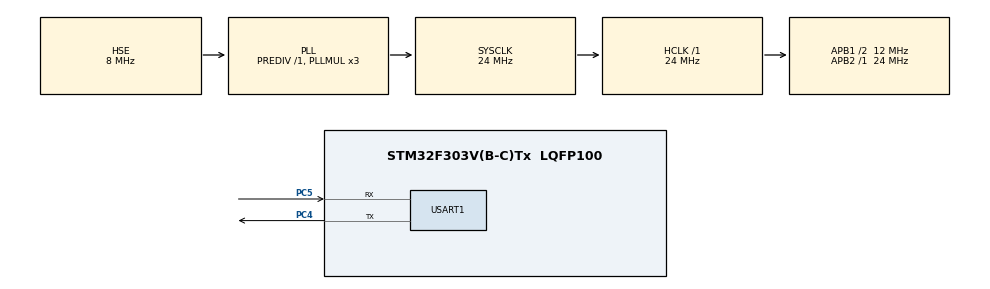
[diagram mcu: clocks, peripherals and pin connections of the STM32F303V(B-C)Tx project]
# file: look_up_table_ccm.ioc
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Mcu.Family=STM32F3
Mcu.Name=STM32F303V(B-C)Tx
Mcu.Package=LQFP100
NVIC.PriorityGroup=NVIC_PRIORITYGROUP_4
NVIC.TIM2_IRQn=true\:0\:0\:false\:false\:true\:true\:true
PC4.Mode=Asynchronous
PC4.Signal=USART1_TX
PC5.Mode=Asynchronous
PC5.Signal=USART1_RX
PF0-OSC_IN.Mode=HSE-External-Oscillator
PF0-OSC_IN.Signal=RCC_OSC_IN
PF1-OSC_OUT.Mode=HSE-External-Oscillator
PF1-OSC_OUT.Signal=RCC_OSC_OUT
ProjectManager.HeapSize=0x200
ProjectManager.StackSize=0x400
ProjectManager.TargetToolchain=STM32CubeIDE
RCC.AHBFreq_Value=24000000
RCC.APB1CLKDivider=RCC_HCLK_DIV2
RCC.APB1Freq_Value=12000000
RCC.APB1TimFreq_Value=24000000
RCC.APB2Freq_Value=24000000
RCC.APB2TimFreq_Value=24000000
RCC.CortexFreq_Value=24000000
RCC.HCLKFreq_Value=24000000
RCC.HSE_VALUE=8000000
RCC.HSI_VALUE=8000000
RCC.LSE_VALUE=32768
RCC.PLLMUL=RCC_PLL_MUL3
RCC.PLLSourceVirtual=RCC_PLLSOURCE_HSE
RCC.SYSCLKFreq_VALUE=24000000
RCC.SYSCLKSourceVirtual=RCC_SYSCLKSOURCE_PLLCLK
RCC.USBFreq_Value=24000000
TIM2.AutoReloadPreload=TIM_AUTORELOAD_PRELOAD_DISABLE
TIM2.Period=(1000000-1)
TIM2.Prescaler=(24-1)
USART1.VirtualMode-Asynchronous=VM_ASYNC
VP_TIM2_VS_ClockSourceINT.Mode=Internal
board=custom

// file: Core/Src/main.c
/* USER CODE BEGIN Header */
/**
  ******************************************************************************
  * @file           : main.c
  * @brief          : Main program body
  ******************************************************************************
  * @attention
  *
  * <h2><center>&copy; Copyright (c) 2021 STMicroelectronics.
  * All rights reserved.</center></h2>
  *
  * This software component is licensed by ST under BSD 3-Clause license,
  * the "License"; You may not use this file except in compliance with the
  * License. You may obtain a copy of the License at:
  *                        opensource.org/licenses/BSD-3-Clause
  *
  ******************************************************************************
  */
/* USER CODE END Header */
#include "main.h"

/* USER CODE BEGIN PM */
TIM_HandleTypeDef htim2;

UART_HandleTypeDef huart1;

/*data size*/
#define INPUT_ARRAY_SIZE_1750

/*functions data*/
#define FUNCTIONS_DATA_IN_FLASH
//#define FUNCTIONS_DATA_IN_CCM

/*program allocation*/
#define PROGRAM_IN_CCM

/*input data allocation*/
#define INPUT_DATA_IN_CCM

float output=0;

/* USER CODE END PM */

TIM_HandleTypeDef htim2;

UART_HandleTypeDef huart1;

/* USER CODE BEGIN PV */
#ifdef PROGRAM_IN_CCM
   __attribute__((section(".ccmram")))
#endif
   void computeArraySin(float * arr_input, float * arr_keys , float * arr_values, int n_lut, int n_input){
       for(int i=0; i<n_input; i++){
           for (int k=0; k<n_lut; k++){
   	        if (*(arr_keys+k+1) >= *(arr_input+i)){
               output = *(arr_values+k) + (*(arr_values+k+1)-*(arr_values+k))*(*(arr_input+i) - *(arr_keys + k))/(*(arr_keys+k+1)-*(arr_keys+k));
               break;
               };
           };
       }
   }

#ifdef FUNCTIONS_DATA_IN_FLASH
   const
#endif
#ifdef FUNCTIONS_DATA_IN_CCM
   __attribute__((section(".ccmramdata")))
#endif
   float arr_keys[721] = {
   0.0, 0.5, 1.0, 1.5, 2.0, 2.5, 3.0, 3.5, 4.0, 4.5, 5.0, 5.5, 6.0, 6.5, 7.0, 7.5, 8.0, 8.5, 9.0, 9.5, 10.0, 10.5, 11.0, 11.5, 12.0, 12.5, 13.0, 13.5, 14.0, 14.5, 15.0, 15.5, 16.0, 16.5, 17.0, 17.5, 18.0, 18.5, 19.0, 19.5, 20.0, 20.5, 21.0, 21.5, 22.0, 22.5, 23.0, 23.5, 24.0, 24.5,
   25.0, 25.5, 26.0, 26.5, 27.0, 27.5, 28.0, 28.5, 29.0, 29.5, 30.0, 30.5, 31.0, 31.5, 32.0, 32.5, 33.0, 33.5, 34.0, 34.5, 35.0, 35.5, 36.0, 36.5, 37.0, 37.5, 38.0, 38.5, 39.0, 39.5, 40.0, 40.5, 41.0, 41.5, 42.0, 42.5, 43.0, 43.5, 44.0, 44.5, 45.0, 45.5, 46.0, 46.5, 47.0, 47.5, 48.0, 48.5, 49.0, 49.5,
   50.0, 50.5, 51.0, 51.5, 52.0, 52.5, 53.0, 53.5, 54.0, 54.5, 55.0, 55.5, 56.0, 56.5, 57.0, 57.5, 58.0, 58.5, 59.0, 59.5, 60.0, 60.5, 61.0, 61.5, 62.0, 62.5, 63.0, 63.5, 64.0, 64.5, 65.0, 65.5, 66.0, 66.5, 67.0, 67.5, 68.0, 68.5, 69.0, 69.5, 70.0, 70.5, 71.0, 71.5, 72.0, 72.5, 73.0, 73.5, 74.0, 74.5,
   75.0, 75.5, 76.0, 76.5, 77.0, 77.5, 78.0, 78.5, 79.0, 79.5, 80.0, 80.5, 81.0, 81.5, 82.0, 82.5, 83.0, 83.5, 84.0, 84.5, 85.0, 85.5, 86.0, 86.5, 87.0, 87.5, 88.0, 88.5, 89.0, 89.5, 90.0, 90.5, 91.0, 91.5, 92.0, 92.5, 93.0, 93.5, 94.0, 94.5, 95.0, 95.5, 96.0, 96.5, 97.0, 97.5, 98.0, 98.5, 99.0, 99.5,
   100.0, 100.5, 101.0, 101.5, 102.0, 102.5, 103.0, 103.5, 104.0, 104.5, 105.0, 105.5, 106.0, 106.5, 107.0, 107.5, 108.0, 108.5, 109.0, 109.5, 110.0, 110.5, 111.0, 111.5, 112.0, 112.5, 113.0, 113.5, 114.0, 114.5, 115.0, 115.5, 116.0, 116.5, 117.0, 117.5, 118.0, 118.5, 119.0, 119.5, 120.0, 120.5, 121.0, 121.5, 122.0, 122.5, 123.0, 123.5, 124.0, 124.5,
   125.0, 125.5, 126.0, 126.5, 127.0, 127.5, 128.0, 128.5, 129.0, 129.5, 130.0, 130.5, 131.0, 131.5, 132.0, 132.5, 133.0, 133.5, 134.0, 134.5, 135.0, 135.5, 136.0, 136.5, 137.0, 137.5, 138.0, 138.5, 139.0, 139.5, 140.0, 140.5, 141.0, 141.5, 142.0, 142.5, 143.0, 143.5, 144.0, 144.5, 145.0, 145.5, 146.0, 146.5, 147.0, 147.5, 148.0, 148.5, 149.0, 149.5,
   150.0, 150.5, 151.0, 151.5, 152.0, 152.5, 153.0, 153.5, 154.0, 154.5, 155.0, 155.5, 156.0, 156.5, 157.0, 157.5, 158.0, 158.5, 159.0, 159.5, 160.0, 160.5, 161.0, 161.5, 162.0, 162.5, 163.0, 163.5, 164.0, 164.5, 165.0, 165.5, 166.0, 166.5, 167.0, 167.5, 168.0, 168.5, 169.0, 169.5, 170.0, 170.5, 171.0, 171.5, 172.0, 172.5, 173.0, 173.5, 174.0, 174.5,
   175.0, 175.5, 176.0, 176.5, 177.0, 177.5, 178.0, 178.5, 179.0, 179.5, 180.0, 180.5, 181.0, 181.5, 182.0, 182.5, 183.0, 183.5, 184.0, 184.5, 185.0, 185.5, 186.0, 186.5, 187.0, 187.5, 188.0, 188.5, 189.0, 189.5, 190.0, 190.5, 191.0, 191.5, 192.0, 192.5, 193.0, 193.5, 194.0, 194.5, 195.0, 195.5, 196.0, 196.5, 197.0, 197.5, 198.0, 198.5, 199.0, 199.5,
   200.0, 200.5, 201.0, 201.5, 202.0, 202.5, 203.0, 203.5, 204.0, 204.5, 205.0, 205.5, 206.0, 206.5, 207.0, 207.5, 208.0, 208.5, 209.0, 209.5, 210.0, 210.5, 211.0, 211.5, 212.0, 212.5, 213.0, 213.5, 214.0, 214.5, 215.0, 215.5, 216.0, 216.5, 217.0, 217.5, 218.0, 218.5, 219.0, 219.5, 220.0, 220.5, 221.0, 221.5, 222.0, 222.5, 223.0, 223.5, 224.0, 224.5,
   225.0, 225.5, 226.0, 226.5, 227.0, 227.5, 228.0, 228.5, 229.0, 229.5, 230.0, 230.5, 231.0, 231.5, 232.0, 232.5, 233.0, 233.5, 234.0, 234.5, 235.0, 235.5, 236.0, 236.5, 237.0, 237.5, 238.0, 238.5, 239.0, 239.5, 240.0, 240.5, 241.0, 241.5, 242.0, 242.5, 243.0, 243.5, 244.0, 244.5, 245.0, 245.5, 246.0, 246.5, 247.0, 247.5, 248.0, 248.5, 249.0, 249.5,
   250.0, 250.5, 251.0, 251.5, 252.0, 252.5, 253.0, 253.5, 254.0, 254.5, 255.0, 255.5, 256.0, 256.5, 257.0, 257.5, 258.0, 258.5, 259.0, 259.5, 260.0, 260.5, 261.0, 261.5, 262.0, 262.5, 263.0, 263.5, 264.0, 264.5, 265.0, 265.5, 266.0, 266.5, 267.0, 267.5, 268.0, 268.5, 269.0, 269.5, 270.0, 270.5, 271.0, 271.5, 272.0, 272.5, 273.0, 273.5, 274.0, 274.5,
   275.0, 275.5, 276.0, 276.5, 277.0, 277.5, 278.0, 278.5, 279.0, 279.5, 280.0, 280.5, 281.0, 281.5, 282.0, 282.5, 283.0, 283.5, 284.0, 284.5, 285.0, 285.5, 286.0, 286.5, 287.0, 287.5, 288.0, 288.5, 289.0, 289.5, 290.0, 290.5, 291.0, 291.5, 292.0, 292.5, 293.0, 293.5, 294.0, 294.5, 295.0, 295.5, 296.0, 296.5, 297.0, 297.5, 298.0, 298.5, 299.0, 299.5,
   300.0, 300.5, 301.0, 301.5, 302.0, 302.5, 303.0, 303.5, 304.0, 304.5, 305.0, 305.5, 306.0, 306.5, 307.0, 307.5, 308.0, 308.5, 309.0, 309.5, 310.0, 310.5, 311.0, 311.5, 312.0, 312.5, 313.0, 313.5, 314.0, 314.5, 315.0, 315.5, 316.0, 316.5, 317.0, 317.5, 318.0, 318.5, 319.0, 319.5, 320.0, 320.5, 321.0, 321.5, 322.0, 322.5, 323.0, 323.5, 324.0, 324.5,
   325.0, 325.5, 326.0, 326.5, 327.0, 327.5, 328.0, 328.5, 329.0, 329.5, 330.0, 330.5, 331.0, 331.5, 332.0, 332.5, 333.0, 333.5, 334.0, 334.5, 335.0, 335.5, 336.0, 336.5, 337.0, 337.5, 338.0, 338.5, 339.0, 339.5, 340.0, 340.5, 341.0, 341.5, 342.0, 342.5, 343.0, 343.5, 344.0, 344.5, 345.0, 345.5, 346.0, 346.5, 347.0, 347.5, 348.0, 348.5, 349.0, 349.5,
   350.0, 350.5, 351.0, 351.5, 352.0, 352.5, 353.0, 353.5, 354.0, 354.5, 355.0, 355.5, 356.0, 356.5, 357.0, 357.5, 358.0, 358.5, 359.0, 359.5, 360.0};

#ifdef FUNCTIONS_DATA_IN_FLASH
   const
#endif
#ifdef FUNCTIONS_DATA_IN_CCM
   __attribute__((section(".ccmramdata")))
#endif
   float arr_values[721] ={
   0.0, 0.0087, 0.0175, 0.0262, 0.0349, 0.0436, 0.0523, 0.061, 0.0698, 0.0785, 0.0872, 0.0958, 0.1045, 0.1132, 0.1219, 0.1305, 0.1392, 0.1478, 0.1564, 0.165, 0.1736, 0.1822, 0.1908, 0.1994, 0.2079, 0.2164, 0.225, 0.2334, 0.2419, 0.2504, 0.2588, 0.2672, 0.2756, 0.284, 0.2924, 0.3007, 0.309, 0.3173, 0.3256, 0.3338, 0.342, 0.3502, 0.3584, 0.3665, 0.3746, 0.3827, 0.3907, 0.3987, 0.4067, 0.4147,
   0.4226, 0.4305, 0.4384, 0.4462, 0.454, 0.4617, 0.4695, 0.4772, 0.4848, 0.4924, 0.5, 0.5075, 0.515, 0.5225, 0.5299, 0.5373, 0.5446, 0.5519, 0.5592, 0.5664, 0.5736, 0.5807, 0.5878, 0.5948, 0.6018, 0.6088, 0.6157, 0.6225, 0.6293, 0.6361, 0.6428, 0.6494, 0.6561, 0.6626, 0.6691, 0.6756, 0.682, 0.6884, 0.6947, 0.7009, 0.7071, 0.7133, 0.7193, 0.7254, 0.7314, 0.7373, 0.7431, 0.749, 0.7547, 0.7604,
   0.766, 0.7716, 0.7771, 0.7826, 0.788, 0.7934, 0.7986, 0.8039, 0.809, 0.8141, 0.8192, 0.8241, 0.829, 0.8339, 0.8387, 0.8434, 0.848, 0.8526, 0.8572, 0.8616, 0.866, 0.8704, 0.8746, 0.8788, 0.8829, 0.887, 0.891, 0.8949, 0.8988, 0.9026, 0.9063, 0.91, 0.9135, 0.9171, 0.9205, 0.9239, 0.9272, 0.9304, 0.9336, 0.9367, 0.9397, 0.9426, 0.9455, 0.9483, 0.9511, 0.9537, 0.9563, 0.9588, 0.9613, 0.9636,
   0.9659, 0.9681, 0.9703, 0.9724, 0.9744, 0.9763, 0.9781, 0.9799, 0.9816, 0.9833, 0.9848, 0.9863, 0.9877, 0.989, 0.9903, 0.9914, 0.9925, 0.9936, 0.9945, 0.9954, 0.9962, 0.9969, 0.9976, 0.9981, 0.9986, 0.999, 0.9994, 0.9997, 0.9998, 1.0, 1.0, 1.0, 0.9998, 0.9997, 0.9994, 0.999, 0.9986, 0.9981, 0.9976, 0.9969, 0.9962, 0.9954, 0.9945, 0.9936, 0.9925, 0.9914, 0.9903, 0.989, 0.9877, 0.9863,
   0.9848, 0.9833, 0.9816, 0.9799, 0.9781, 0.9763, 0.9744, 0.9724, 0.9703, 0.9681, 0.9659, 0.9636, 0.9613, 0.9588, 0.9563, 0.9537, 0.9511, 0.9483, 0.9455, 0.9426, 0.9397, 0.9367, 0.9336, 0.9304, 0.9272, 0.9239, 0.9205, 0.9171, 0.9135, 0.91, 0.9063, 0.9026, 0.8988, 0.8949, 0.891, 0.887, 0.8829, 0.8788, 0.8746, 0.8704, 0.866, 0.8616, 0.8572, 0.8526, 0.848, 0.8434, 0.8387, 0.8339, 0.829, 0.8241,
   0.8192, 0.8141, 0.809, 0.8039, 0.7986, 0.7934, 0.788, 0.7826, 0.7771, 0.7716, 0.766, 0.7604, 0.7547, 0.749, 0.7431, 0.7373, 0.7314, 0.7254, 0.7193, 0.7133, 0.7071, 0.7009, 0.6947, 0.6884, 0.682, 0.6756, 0.6691, 0.6626, 0.6561, 0.6494, 0.6428, 0.6361, 0.6293, 0.6225, 0.6157, 0.6088, 0.6018, 0.5948, 0.5878, 0.5807, 0.5736, 0.5664, 0.5592, 0.5519, 0.5446, 0.5373, 0.5299, 0.5225, 0.515, 0.5075,
   0.5, 0.4924, 0.4848, 0.4772, 0.4695, 0.4617, 0.454, 0.4462, 0.4384, 0.4305, 0.4226, 0.4147, 0.4067, 0.3987, 0.3907, 0.3827, 0.3746, 0.3665, 0.3584, 0.3502, 0.342, 0.3338, 0.3256, 0.3173, 0.309, 0.3007, 0.2924, 0.284, 0.2756, 0.2672, 0.2588, 0.2504, 0.2419, 0.2334, 0.225, 0.2164, 0.2079, 0.1994, 0.1908, 0.1822, 0.1736, 0.165, 0.1564, 0.1478, 0.1392, 0.1305, 0.1219, 0.1132, 0.1045, 0.0958,
   0.0872, 0.0785, 0.0698, 0.061, 0.0523, 0.0436, 0.0349, 0.0262, 0.0175, 0.0087, 0.0, -0.0087, -0.0175, -0.0262, -0.0349, -0.0436, -0.0523, -0.061, -0.0698, -0.0785, -0.0872, -0.0958, -0.1045, -0.1132, -0.1219, -0.1305, -0.1392, -0.1478, -0.1564, -0.165, -0.1736, -0.1822, -0.1908, -0.1994, -0.2079, -0.2164, -0.225, -0.2334, -0.2419, -0.2504, -0.2588, -0.2672, -0.2756, -0.284, -0.2924, -0.3007, -0.309, -0.3173, -0.3256, -0.3338,
   -0.342, -0.3502, -0.3584, -0.3665, -0.3746, -0.3827, -0.3907, -0.3987, -0.4067, -0.4147, -0.4226, -0.4305, -0.4384, -0.4462, -0.454, -0.4617, -0.4695, -0.4772, -0.4848, -0.4924, -0.5, -0.5075, -0.515, -0.5225, -0.5299, -0.5373, -0.5446, -0.5519, -0.5592, -0.5664, -0.5736, -0.5807, -0.5878, -0.5948, -0.6018, -0.6088, -0.6157, -0.6225, -0.6293, -0.6361, -0.6428, -0.6494, -0.6561, -0.6626, -0.6691, -0.6756, -0.682, -0.6884, -0.6947, -0.7009,
   -0.7071, -0.7133, -0.7193, -0.7254, -0.7314, -0.7373, -0.7431, -0.749, -0.7547, -0.7604, -0.766, -0.7716, -0.7771, -0.7826, -0.788, -0.7934, -0.7986, -0.8039, -0.809, -0.8141, -0.8192, -0.8241, -0.829, -0.8339, -0.8387, -0.8434, -0.848, -0.8526, -0.8572, -0.8616, -0.866, -0.8704, -0.8746, -0.8788, -0.8829, -0.887, -0.891, -0.8949, -0.8988, -0.9026, -0.9063, -0.91, -0.9135, -0.9171, -0.9205, -0.9239, -0.9272, -0.9304, -0.9336, -0.9367,
   -0.9397, -0.9426, -0.9455, -0.9483, -0.9511, -0.9537, -0.9563, -0.9588, -0.9613, -0.9636, -0.9659, -0.9681, -0.9703, -0.9724, -0.9744, -0.9763, -0.9781, -0.9799, -0.9816, -0.9833, -0.9848, -0.9863, -0.9877, -0.989, -0.9903, -0.9914, -0.9925, -0.9936, -0.9945, -0.9954, -0.9962, -0.9969, -0.9976, -0.9981, -0.9986, -0.999, -0.9994, -0.9997, -0.9998, -1.0, -1.0, -1.0, -0.9998, -0.9997, -0.9994, -0.999, -0.9986, -0.9981, -0.9976, -0.9969,
   -0.9962, -0.9954, -0.9945, -0.9936, -0.9925, -0.9914, -0.9903, -0.989, -0.9877, -0.9863, -0.9848, -0.9833, -0.9816, -0.9799, -0.9781, -0.9763, -0.9744, -0.9724, -0.9703, -0.9681, -0.9659, -0.9636, -0.9613, -0.9588, -0.9563, -0.9537, -0.9511, -0.9483, -0.9455, -0.9426, -0.9397, -0.9367, -0.9336, -0.9304, -0.9272, -0.9239, -0.9205, -0.9171, -0.9135, -0.91, -0.9063, -0.9026, -0.8988, -0.8949, -0.891, -0.887, -0.8829, -0.8788, -0.8746, -0.8704,
   -0.866, -0.8616, -0.8572, -0.8526, -0.848, -0.8434, -0.8387, -0.8339, -0.829, -0.8241, -0.8192, -0.8141, -0.809, -0.8039, -0.7986, -0.7934, -0.788, -0.7826, -0.7771, -0.7716, -0.766, -0.7604, -0.7547, -0.749, -0.7431, -0.7373, -0.7314, -0.7254, -0.7193, -0.7133, -0.7071, -0.7009, -0.6947, -0.6884, -0.682, -0.6756, -0.6691, -0.6626, -0.6561, -0.6494, -0.6428, -0.6361, -0.6293, -0.6225, -0.6157, -0.6088, -0.6018, -0.5948, -0.5878, -0.5807,
   -0.5736, -0.5664, -0.5592, -0.5519, -0.5446, -0.5373, -0.5299, -0.5225, -0.515, -0.5075, -0.5, -0.4924, -0.4848, -0.4772, -0.4695, -0.4617, -0.454, -0.4462, -0.4384, -0.4305, -0.4226, -0.4147, -0.4067, -0.3987, -0.3907, -0.3827, -0.3746, -0.3665, -0.3584, -0.3502, -0.342, -0.3338, -0.3256, -0.3173, -0.309, -0.3007, -0.2924, -0.284, -0.2756, -0.2672, -0.2588, -0.2504, -0.2419, -0.2334, -0.225, -0.2164, -0.2079, -0.1994, -0.1908, -0.1822,
   -0.1736, -0.165, -0.1564, -0.1478, -0.1392, -0.1305, -0.1219, -0.1132, -0.1045, -0.0958, -0.0872, -0.0785, -0.0698, -0.061, -0.0523, -0.0436, -0.0349, -0.0262, -0.0175, -0.0087, -0.0};

#ifdef INPUT_ARRAY_SIZE_100
#ifdef INPUT_DATA_IN_CCM
   __attribute__((section(".ccmramdata")))
#endif

   float arr_input[100] ={ 48.3711 ,305.0761 ,274.9589 ,91.8248 ,178.3566 ,161.8168 ,234.5735 ,283.9404 ,33.7895 ,10.2051 ,300.8754 ,155.7961 ,274.4208 ,0.7582 ,160.3394 ,259.7544 ,82.3544 ,340.2975 ,324.5139 ,11.0124 ,9.1605 ,194.9085 ,338.0937 ,137.2335 ,77.9758 ,151.9620 ,10.4547 ,79.8090 ,157.6395 ,178.4924 ,83.9104 ,83.1120 ,78.7612 ,165.4572 ,104.3214 ,7.7363 ,301.5281 ,200.3236 ,231.2260 ,66.9263 ,357.3156 ,309.5808 ,43.5204 ,119.7703 ,259.7344 ,256.0290 ,337.1186 ,151.9585 ,298.8128 ,241.3100 ,
      		109.2127 ,211.5290 ,317.6924 ,304.6311 ,181.9022 ,212.0408 ,12.4293 ,87.3864 ,287.0655 ,149.1530 ,62.2827 ,197.5676 ,253.0947 ,242.8149 ,134.8931 ,158.0262 ,183.0335 ,280.2393 ,187.5378 ,141.5718 ,176.2897 ,10.6470 ,15.6554 ,253.2176 ,353.9476 ,213.5461 ,141.6959 ,61.3257 ,180.8059 ,353.5476 ,277.3883 ,194.2623 ,309.7043 ,83.5834 ,184.9578 ,342.8883 ,208.0061 ,165.2874 ,96.9406 ,197.2787 ,344.5619 ,2.0553 ,282.1159 ,295.3749 ,319.0246 ,266.5812 ,291.2904 ,186.7242 ,202.0888 ,153.3926};
#endif

#ifdef INPUT_ARRAY_SIZE_200
#ifdef INPUT_DATA_IN_CCM
   __attribute__((section(".ccmramdata")))
#endif
   float arr_input[200] = {48.3711 ,305.0761 ,274.9589 ,91.8248 ,178.3566 ,161.8168 ,234.5735 ,283.9404 ,33.7895 ,10.2051 ,300.8754 ,155.7961 ,274.4208 ,0.7582 ,160.3394 ,259.7544 ,82.3544 ,340.2975 ,324.5139 ,11.0124 ,9.1605 ,194.9085 ,338.0937 ,137.2335 ,77.9758 ,151.9620 ,10.4547 ,79.8090 ,157.6395 ,178.4924 ,83.9104 ,83.1120 ,78.7612 ,165.4572 ,104.3214 ,7.7363 ,301.5281 ,200.3236 ,231.2260 ,66.9263 ,357.3156 ,309.5808 ,43.5204 ,119.7703 ,259.7344 ,256.0290 ,337.1186 ,151.9585 ,298.8128 ,241.3100 ,
    		109.2127 ,211.5290 ,317.6924 ,304.6311 ,181.9022 ,212.0408 ,12.4293 ,87.3864 ,287.0655 ,149.1530 ,62.2827 ,197.5676 ,253.0947 ,242.8149 ,134.8931 ,158.0262 ,183.0335 ,280.2393 ,187.5378 ,141.5718 ,176.2897 ,10.6470 ,15.6554 ,253.2176 ,353.9476 ,213.5461 ,141.6959 ,61.3257 ,180.8059 ,353.5476 ,277.3883 ,194.2623 ,309.7043 ,83.5834 ,184.9578 ,342.8883 ,208.0061 ,165.2874 ,96.9406 ,197.2787 ,344.5619 ,2.0553 ,282.1159 ,295.3749 ,319.0246 ,266.5812 ,291.2904 ,186.7242 ,202.0888 ,153.3926 ,
    		20.2044 ,313.2037 ,205.1998 ,71.9422 ,181.6994 ,174.5730 ,128.4444 ,124.5881 ,193.8524 ,224.4562 ,220.4829 ,164.9328 ,10.0710 ,82.6578 ,63.7961 ,210.4059 ,309.9632 ,287.4380 ,286.9551 ,293.9175 ,91.9059 ,303.0281 ,242.3209 ,29.9643 ,6.0086 ,5.2416 ,272.0112 ,89.8413 ,39.4159 ,224.9288 ,123.9922 ,25.0255 ,57.4652 ,189.8569 ,60.5322 ,98.2492 ,256.1724 ,163.6926 ,115.9206 ,170.5576 ,8.5084 ,139.1606 ,151.5307 ,67.6941 ,39.1542 ,323.9347 ,183.6418 ,75.2728 ,218.0335 ,294.1343 ,
    		7.4945 ,6.4312 ,52.7262 ,258.7808 ,57.6819 ,253.6580 ,244.1433 ,196.0928 ,79.4159 ,351.2140 ,287.2119 ,185.9758 ,80.3505 ,233.4623 ,142.1633 ,207.3045 ,115.6485 ,227.1412 ,21.1626 ,107.4981 ,348.4452 ,315.1923 ,110.2992 ,309.0652 ,111.7309 ,338.1438 ,267.7832 ,149.8220 ,90.8489 ,3.0529 ,316.3384 ,13.6500 ,294.9891 ,346.3924 ,205.3010 ,61.7462 ,312.4012 ,350.5591 ,253.4483 ,183.1945 ,136.0688 ,124.8951 ,74.0742 ,242.6951 ,155.8620 ,69.8827 ,37.5927 ,239.7447 ,106.5862 ,179.9280};
#endif

#ifdef INPUT_ARRAY_SIZE_300
#ifdef INPUT_DATA_IN_CCM
   __attribute__((section(".ccmramdata")))
#endif
   float arr_input[300] = {48.3711 ,305.0761 ,274.9589 ,91.8248 ,178.3566 ,161.8168 ,234.5735 ,283.9404 ,33.7895 ,10.2051 ,300.8754 ,155.7961 ,274.4208 ,0.7582 ,160.3394 ,259.7544 ,82.3544 ,340.2975 ,324.5139 ,11.0124 ,9.1605 ,194.9085 ,338.0937 ,137.2335 ,77.9758 ,151.9620 ,10.4547 ,79.8090 ,157.6395 ,178.4924 ,83.9104 ,83.1120 ,78.7612 ,165.4572 ,104.3214 ,7.7363 ,301.5281 ,200.3236 ,231.2260 ,66.9263 ,357.3156 ,309.5808 ,43.5204 ,119.7703 ,259.7344 ,256.0290 ,337.1186 ,151.9585 ,298.8128 ,241.3100 ,
      		109.2127 ,211.5290 ,317.6924 ,304.6311 ,181.9022 ,212.0408 ,12.4293 ,87.3864 ,287.0655 ,149.1530 ,62.2827 ,197.5676 ,253.0947 ,242.8149 ,134.8931 ,158.0262 ,183.0335 ,280.2393 ,187.5378 ,141.5718 ,176.2897 ,10.6470 ,15.6554 ,253.2176 ,353.9476 ,213.5461 ,141.6959 ,61.3257 ,180.8059 ,353.5476 ,277.3883 ,194.2623 ,309.7043 ,83.5834 ,184.9578 ,342.8883 ,208.0061 ,165.2874 ,96.9406 ,197.2787 ,344.5619 ,2.0553 ,282.1159 ,295.3749 ,319.0246 ,266.5812 ,291.2904 ,186.7242 ,202.0888 ,153.3926 ,
      		20.2044 ,313.2037 ,205.1998 ,71.9422 ,181.6994 ,174.5730 ,128.4444 ,124.5881 ,193.8524 ,224.4562 ,220.4829 ,164.9328 ,10.0710 ,82.6578 ,63.7961 ,210.4059 ,309.9632 ,287.4380 ,286.9551 ,293.9175 ,91.9059 ,303.0281 ,242.3209 ,29.9643 ,6.0086 ,5.2416 ,272.0112 ,89.8413 ,39.4159 ,224.9288 ,123.9922 ,25.0255 ,57.4652 ,189.8569 ,60.5322 ,98.2492 ,256.1724 ,163.6926 ,115.9206 ,170.5576 ,8.5084 ,139.1606 ,151.5307 ,67.6941 ,39.1542 ,323.9347 ,183.6418 ,75.2728 ,218.0335 ,294.1343 ,
      		7.4945 ,6.4312 ,52.7262 ,258.7808 ,57.6819 ,253.6580 ,244.1433 ,196.0928 ,79.4159 ,351.2140 ,287.2119 ,185.9758 ,80.3505 ,233.4623 ,142.1633 ,207.3045 ,115.6485 ,227.1412 ,21.1626 ,107.4981 ,348.4452 ,315.1923 ,110.2992 ,309.0652 ,111.7309 ,338.1438 ,267.7832 ,149.8220 ,90.8489 ,3.0529 ,316.3384 ,13.6500 ,294.9891 ,346.3924 ,205.3010 ,61.7462 ,312.4012 ,350.5591 ,253.4483 ,183.1945 ,136.0688 ,124.8951 ,74.0742 ,242.6951 ,155.8620 ,69.8827 ,37.5927 ,239.7447 ,106.5862 ,179.9280 ,
      		117.1244 ,313.7837 ,323.8842 ,6.5135 ,72.3071 ,117.9867 ,355.3379 ,281.7721 ,122.0744 ,76.6907 ,242.8038 ,301.5724 ,335.5875 ,123.7859 ,317.6616 ,247.3597 ,174.4195 ,354.7830 ,84.4706 ,261.1675 ,30.4849 ,61.0899 ,327.9556 ,76.6686 ,273.2818 ,216.0752 ,302.8076 ,132.5189 ,122.5027 ,104.8375 ,312.2711 ,217.4337 ,343.5507 ,319.4154 ,48.7246 ,198.4214 ,37.5390 ,14.0896 ,26.3496 ,311.8206 ,283.7219 ,298.2621 ,122.7231 ,221.4670 ,281.4853 ,136.0943 ,205.4813 ,80.5371 ,29.4276 ,96.0205 ,
      		320.6765 ,203.2009 ,333.0242 ,164.7969 ,99.7858 ,283.3253 ,297.9965 ,4.4574 ,241.3482 ,33.0059 ,41.4369 ,318.6216 ,14.4085 ,86.2680 ,355.7371 ,151.5649 ,41.6009 ,60.2580 ,86.9113 ,267.8423 ,37.0203 ,327.8752 ,136.1798 ,349.2951 ,327.3202 ,105.8485 ,91.2276 ,171.7236 ,36.0465 ,234.7381 ,14.2633 ,3.7822 ,353.7301 ,106.3979 ,214.7654 ,161.9440 ,112.7811 ,22.6673 ,328.8211 ,349.1328 ,349.1267 ,40.0904 ,77.4696 ,222.4105 ,352.7830 ,195.4488 ,247.7483 ,238.2604 ,93.2710 ,194.9768};
#endif

#ifdef INPUT_ARRAY_SIZE_400
#ifdef INPUT_DATA_IN_CCM
   __attribute__((section(".ccmramdata")))
#endif
   float arr_input[400] = {48.3711 ,305.0761 ,274.9589 ,91.8248 ,178.3566 ,161.8168 ,234.5735 ,283.9404 ,33.7895 ,10.2051 ,300.8754 ,155.7961 ,274.4208 ,0.7582 ,160.3394 ,259.7544 ,82.3544 ,340.2975 ,324.5139 ,11.0124 ,9.1605 ,194.9085 ,338.0937 ,137.2335 ,77.9758 ,151.9620 ,10.4547 ,79.8090 ,157.6395 ,178.4924 ,83.9104 ,83.1120 ,78.7612 ,165.4572 ,104.3214 ,7.7363 ,301.5281 ,200.3236 ,231.2260 ,66.9263 ,357.3156 ,309.5808 ,43.5204 ,119.7703 ,259.7344 ,256.0290 ,337.1186 ,151.9585 ,298.8128 ,241.3100 ,
      		109.2127 ,211.5290 ,317.6924 ,304.6311 ,181.9022 ,212.0408 ,12.4293 ,87.3864 ,287.0655 ,149.1530 ,62.2827 ,197.5676 ,253.0947 ,242.8149 ,134.8931 ,158.0262 ,183.0335 ,280.2393 ,187.5378 ,141.5718 ,176.2897 ,10.6470 ,15.6554 ,253.2176 ,353.9476 ,213.5461 ,141.6959 ,61.3257 ,180.8059 ,353.5476 ,277.3883 ,194.2623 ,309.7043 ,83.5834 ,184.9578 ,342.8883 ,208.0061 ,165.2874 ,96.9406 ,197.2787 ,344.5619 ,2.0553 ,282.1159 ,295.3749 ,319.0246 ,266.5812 ,291.2904 ,186.7242 ,202.0888 ,153.3926 ,
      		20.2044 ,313.2037 ,205.1998 ,71.9422 ,181.6994 ,174.5730 ,128.4444 ,124.5881 ,193.8524 ,224.4562 ,220.4829 ,164.9328 ,10.0710 ,82.6578 ,63.7961 ,210.4059 ,309.9632 ,287.4380 ,286.9551 ,293.9175 ,91.9059 ,303.0281 ,242.3209 ,29.9643 ,6.0086 ,5.2416 ,272.0112 ,89.8413 ,39.4159 ,224.9288 ,123.9922 ,25.0255 ,57.4652 ,189.8569 ,60.5322 ,98.2492 ,256.1724 ,163.6926 ,115.9206 ,170.5576 ,8.5084 ,139.1606 ,151.5307 ,67.6941 ,39.1542 ,323.9347 ,183.6418 ,75.2728 ,218.0335 ,294.1343 ,
      		7.4945 ,6.4312 ,52.7262 ,258.7808 ,57.6819 ,253.6580 ,244.1433 ,196.0928 ,79.4159 ,351.2140 ,287.2119 ,185.9758 ,80.3505 ,233.4623 ,142.1633 ,207.3045 ,115.6485 ,227.1412 ,21.1626 ,107.4981 ,348.4452 ,315.1923 ,110.2992 ,309.0652 ,111.7309 ,338.1438 ,267.7832 ,149.8220 ,90.8489 ,3.0529 ,316.3384 ,13.6500 ,294.9891 ,346.3924 ,205.3010 ,61.7462 ,312.4012 ,350.5591 ,253.4483 ,183.1945 ,136.0688 ,124.8951 ,74.0742 ,242.6951 ,155.8620 ,69.8827 ,37.5927 ,239.7447 ,106.5862 ,179.9280 ,
      		117.1244 ,313.7837 ,323.8842 ,6.5135 ,72.3071 ,117.9867 ,355.3379 ,281.7721 ,122.0744 ,76.6907 ,242.8038 ,301.5724 ,335.5875 ,123.7859 ,317.6616 ,247.3597 ,174.4195 ,354.7830 ,84.4706 ,261.1675 ,30.4849 ,61.0899 ,327.9556 ,76.6686 ,273.2818 ,216.0752 ,302.8076 ,132.5189 ,122.5027 ,104.8375 ,312.2711 ,217.4337 ,343.5507 ,319.4154 ,48.7246 ,198.4214 ,37.5390 ,14.0896 ,26.3496 ,311.8206 ,283.7219 ,298.2621 ,122.7231 ,221.4670 ,281.4853 ,136.0943 ,205.4813 ,80.5371 ,29.4276 ,96.0205 ,
      		320.6765 ,203.2009 ,333.0242 ,164.7969 ,99.7858 ,283.3253 ,297.9965 ,4.4574 ,241.3482 ,33.0059 ,41.4369 ,318.6216 ,14.4085 ,86.2680 ,355.7371 ,151.5649 ,41.6009 ,60.2580 ,86.9113 ,267.8423 ,37.0203 ,327.8752 ,136.1798 ,349.2951 ,327.3202 ,105.8485 ,91.2276 ,171.7236 ,36.0465 ,234.7381 ,14.2633 ,3.7822 ,353.7301 ,106.3979 ,214.7654 ,161.9440 ,112.7811 ,22.6673 ,328.8211 ,349.1328 ,349.1267 ,40.0904 ,77.4696 ,222.4105 ,352.7830 ,195.4488 ,247.7483 ,238.2604 ,93.2710 ,194.9768 ,
      		110.6356 ,88.6972 ,29.2928 ,101.0832 ,354.0156 ,161.2448 ,234.7238 ,231.6478 ,338.6644 ,140.5723 ,110.4423 ,117.8069 ,114.0247 ,304.9685 ,321.6601 ,109.0114 ,120.3600 ,195.9211 ,208.4348 ,214.5465 ,88.2353 ,7.3347 ,87.7533 ,26.0379 ,198.4337 ,25.5299 ,27.0467 ,228.7376 ,104.6958 ,285.1865 ,177.5740 ,310.5536 ,55.5047 ,180.5147 ,286.1941 ,27.7585 ,341.7221 ,62.3672 ,279.4352 ,354.5625 ,295.7581 ,115.1222 ,38.4760 ,185.1690 ,330.9685 ,105.6562 ,321.7532 ,51.0050 ,327.7734 ,11.4336 ,
      		113.7847 ,325.1118 ,289.3883 ,326.5754 ,302.6587 ,268.6266 ,248.2543 ,64.1358 ,155.7497 ,56.8429 ,257.3368 ,240.4003 ,90.9311 ,23.1891 ,346.8189 ,290.9709 ,197.7372 ,194.8960 ,306.4654 ,163.1915 ,142.4558 ,121.9209 ,92.8689 ,8.7871 ,232.7180 ,150.0062 ,205.4173 ,22.4358 ,127.7796 ,49.7823 ,45.0464 ,93.2807 ,298.4164 ,143.2070 ,144.3896 ,220.4802 ,84.0707 ,2.6918 ,190.3326 ,180.3239 ,233.5823 ,157.7941 ,247.1447 ,263.3119 ,85.8149 ,178.2260 ,172.3777 ,81.0224 ,148.4086 ,201.7467};
#endif

#ifdef INPUT_ARRAY_SIZE_500
#ifdef INPUT_DATA_IN_CCM
   __attribute__((section(".ccmramdata")))
#endif
   float arr_input[500] = {48.3711 ,305.0761 ,274.9589 ,91.8248 ,178.3566 ,161.8168 ,234.5735 ,283.9404 ,33.7895 ,10.2051 ,300.8754 ,155.7961 ,274.4208 ,0.7582 ,160.3394 ,259.7544 ,82.3544 ,340.2975 ,324.5139 ,11.0124 ,9.1605 ,194.9085 ,338.0937 ,137.2335 ,77.9758 ,151.9620 ,10.4547 ,79.8090 ,157.6395 ,178.4924 ,83.9104 ,83.1120 ,78.7612 ,165.4572 ,104.3214 ,7.7363 ,301.5281 ,200.3236 ,231.2260 ,66.9263 ,357.3156 ,309.5808 ,43.5204 ,119.7703 ,259.7344 ,256.0290 ,337.1186 ,151.9585 ,298.8128 ,241.3100 ,
      		109.2127 ,211.5290 ,317.6924 ,304.6311 ,181.9022 ,212.0408 ,12.4293 ,87.3864 ,287.0655 ,149.1530 ,62.2827 ,197.5676 ,253.0947 ,242.8149 ,134.8931 ,158.0262 ,183.0335 ,280.2393 ,187.5378 ,141.5718 ,176.2897 ,10.6470 ,15.6554 ,253.2176 ,353.9476 ,213.5461 ,141.6959 ,61.3257 ,180.8059 ,353.5476 ,277.3883 ,194.2623 ,309.7043 ,83.5834 ,184.9578 ,342.8883 ,208.0061 ,165.2874 ,96.9406 ,197.2787 ,344.5619 ,2.0553 ,282.1159 ,295.3749 ,319.0246 ,266.5812 ,291.2904 ,186.7242 ,202.0888 ,153.3926 ,
      		20.2044 ,313.2037 ,205.1998 ,71.9422 ,181.6994 ,174.5730 ,128.4444 ,124.5881 ,193.8524 ,224.4562 ,220.4829 ,164.9328 ,10.0710 ,82.6578 ,63.7961 ,210.4059 ,309.9632 ,287.4380 ,286.9551 ,293.9175 ,91.9059 ,303.0281 ,242.3209 ,29.9643 ,6.0086 ,5.2416 ,272.0112 ,89.8413 ,39.4159 ,224.9288 ,123.9922 ,25.0255 ,57.4652 ,189.8569 ,60.5322 ,98.2492 ,256.1724 ,163.6926 ,115.9206 ,170.5576 ,8.5084 ,139.1606 ,151.5307 ,67.6941 ,39.1542 ,323.9347 ,183.6418 ,75.2728 ,218.0335 ,294.1343 ,
      		7.4945 ,6.4312 ,52.7262 ,258.7808 ,57.6819 ,253.6580 ,244.1433 ,196.0928 ,79.4159 ,351.2140 ,287.2119 ,185.9758 ,80.3505 ,233.4623 ,142.1633 ,207.3045 ,115.6485 ,227.1412 ,21.1626 ,107.4981 ,348.4452 ,315.1923 ,110.2992 ,309.0652 ,111.7309 ,338.1438 ,267.7832 ,149.8220 ,90.8489 ,3.0529 ,316.3384 ,13.6500 ,294.9891 ,346.3924 ,205.3010 ,61.7462 ,312.4012 ,350.5591 ,253.4483 ,183.1945 ,136.0688 ,124.8951 ,74.0742 ,242.6951 ,155.8620 ,69.8827 ,37.5927 ,239.7447 ,106.5862 ,179.9280 ,
      		117.1244 ,313.7837 ,323.8842 ,6.5135 ,72.3071 ,117.9867 ,355.3379 ,281.7721 ,122.0744 ,76.6907 ,242.8038 ,301.5724 ,335.5875 ,123.7859 ,317.6616 ,247.3597 ,174.4195 ,354.7830 ,84.4706 ,261.1675 ,30.4849 ,61.0899 ,327.9556 ,76.6686 ,273.2818 ,216.0752 ,302.8076 ,132.5189 ,122.5027 ,104.8375 ,312.2711 ,217.4337 ,343.5507 ,319.4154 ,48.7246 ,198.4214 ,37.5390 ,14.0896 ,26.3496 ,311.8206 ,283.7219 ,298.2621 ,122.7231 ,221.4670 ,281.4853 ,136.0943 ,205.4813 ,80.5371 ,29.4276 ,96.0205 ,
      		320.6765 ,203.2009 ,333.0242 ,164.7969 ,99.7858 ,283.3253 ,297.9965 ,4.4574 ,241.3482 ,33.0059 ,41.4369 ,318.6216 ,14.4085 ,86.2680 ,355.7371 ,151.5649 ,41.6009 ,60.2580 ,86.9113 ,267.8423 ,37.0203 ,327.8752 ,136.1798 ,349.2951 ,327.3202 ,105.8485 ,91.2276 ,171.7236 ,36.0465 ,234.7381 ,14.2633 ,3.7822 ,353.7301 ,106.3979 ,214.7654 ,161.9440 ,112.7811 ,22.6673 ,328.8211 ,349.1328 ,349.1267 ,40.0904 ,77.4696 ,222.4105 ,352.7830 ,195.4488 ,247.7483 ,238.2604 ,93.2710 ,194.9768 ,
      		110.6356 ,88.6972 ,29.2928 ,101.0832 ,354.0156 ,161.2448 ,234.7238 ,231.6478 ,338.6644 ,140.5723 ,110.4423 ,117.8069 ,114.0247 ,304.9685 ,321.6601 ,109.0114 ,120.3600 ,195.9211 ,208.4348 ,214.5465 ,88.2353 ,7.3347 ,87.7533 ,26.0379 ,198.4337 ,25.5299 ,27.0467 ,228.7376 ,104.6958 ,285.1865 ,177.5740 ,310.5536 ,55.5047 ,180.5147 ,286.1941 ,27.7585 ,341.7221 ,62.3672 ,279.4352 ,354.5625 ,295.7581 ,115.1222 ,38.4760 ,185.1690 ,330.9685 ,105.6562 ,321.7532 ,51.0050 ,327.7734 ,11.4336 ,
      		113.7847 ,325.1118 ,289.3883 ,326.5754 ,302.6587 ,268.6266 ,248.2543 ,64.1358 ,155.7497 ,56.8429 ,257.3368 ,240.4003 ,90.9311 ,23.1891 ,346.8189 ,290.9709 ,197.7372 ,194.8960 ,306.4654 ,163.1915 ,142.4558 ,121.9209 ,92.8689 ,8.7871 ,232.7180 ,150.0062 ,205.4173 ,22.4358 ,127.7796 ,49.7823 ,45.0464 ,93.2807 ,298.4164 ,143.2070 ,144.3896 ,220.4802 ,84.0707 ,2.6918 ,190.3326 ,180.3239 ,233.5823 ,157.7941 ,247.1447 ,263.3119 ,85.8149 ,178.2260 ,172.3777 ,81.0224 ,148.4086 ,201.7467 ,
      		326.4982 ,330.3744 ,99.0811 ,232.7095 ,17.3510 ,25.7585 ,184.2090 ,315.8727 ,57.4084 ,275.7700 ,317.8834 ,112.2487 ,249.3205 ,305.6368 ,133.7812 ,252.4618 ,265.1105 ,214.0480 ,308.2598 ,322.7776 ,345.6284 ,205.6438 ,63.4593 ,90.2143 ,78.3427 ,205.0262 ,272.7900 ,18.7680 ,245.3891 ,258.1752 ,125.2733 ,185.4201 ,59.3273 ,262.7626 ,14.6551 ,353.2396 ,290.8597 ,226.2415 ,96.3094 ,328.6306 ,345.3980 ,50.0854 ,279.2726 ,303.0951 ,237.4982 ,252.1468 ,160.2211 ,332.7508 ,349.6347 ,137.6472 ,
      		288.9762 ,155.8518 ,59.3115 ,117.1682 ,45.4788 ,327.1985 ,345.3927 ,42.9072 ,216.2445 ,146.9607 ,42.5124 ,106.3712 ,89.3579 ,269.8477 ,1.4432 ,68.3419 ,157.9583 ,7.5725 ,225.9096 ,218.0259 ,300.7196 ,74.3781 ,102.5214 ,195.2422 ,98.3613 ,210.8657 ,90.3176 ,246.0698 ,284.7927 ,291.1157 ,350.5018 ,196.3357 ,176.6913 ,308.0512 ,276.8643 ,205.3961 ,137.9723 ,102.2571 ,38.9301 ,290.7177 ,42.5058 ,269.0155 ,196.3034 ,347.3803 ,273.9836 ,350.4671 ,49.1738 ,180.1337 ,206.1282 ,112.0505};
#endif

#ifdef INPUT_ARRAY_SIZE_750
#ifdef INPUT_DATA_IN_CCM
   __attribute__((section(".ccmramdata")))
#endif
      float arr_input[750] ={48.3711 ,305.0761 ,274.9589 ,91.8248 ,178.3566 ,161.8168 ,234.5735 ,283.9404 ,33.7895 ,10.2051 ,300.8754 ,155.7961 ,274.4208 ,0.7582 ,160.3394 ,259.7544 ,82.3544 ,340.2975 ,324.5139 ,11.0124 ,9.1605 ,194.9085 ,338.0937 ,137.2335 ,77.9758 ,151.9620 ,10.4547 ,79.8090 ,157.6395 ,178.4924 ,83.9104 ,83.1120 ,78.7612 ,165.4572 ,104.3214 ,7.7363 ,301.5281 ,200.3236 ,231.2260 ,66.9263 ,357.3156 ,309.5808 ,43.5204 ,119.7703 ,259.7344 ,256.0290 ,337.1186 ,151.9585 ,298.8128 ,241.3100 ,
      		109.2127 ,211.5290 ,317.6924 ,304.6311 ,181.9022 ,212.0408 ,12.4293 ,87.3864 ,287.0655 ,149.1530 ,62.2827 ,197.5676 ,253.0947 ,242.8149 ,134.8931 ,158.0262 ,183.0335 ,280.2393 ,187.5378 ,141.5718 ,176.2897 ,10.6470 ,15.6554 ,253.2176 ,353.9476 ,213.5461 ,141.6959 ,61.3257 ,180.8059 ,353.5476 ,277.3883 ,194.2623 ,309.7043 ,83.5834 ,184.9578 ,342.8883 ,208.0061 ,165.2874 ,96.9406 ,197.2787 ,344.5619 ,2.0553 ,282.1159 ,295.3749 ,319.0246 ,266.5812 ,291.2904 ,186.7242 ,202.0888 ,153.3926 ,
      		20.2044 ,313.2037 ,205.1998 ,71.9422 ,181.6994 ,174.5730 ,128.4444 ,124.5881 ,193.8524 ,224.4562 ,220.4829 ,164.9328 ,10.0710 ,82.6578 ,63.7961 ,210.4059 ,309.9632 ,287.4380 ,286.9551 ,293.9175 ,91.9059 ,303.0281 ,242.3209 ,29.9643 ,6.0086 ,5.2416 ,272.0112 ,89.8413 ,39.4159 ,224.9288 ,123.9922 ,25.0255 ,57.4652 ,189.8569 ,60.5322 ,98.2492 ,256.1724 ,163.6926 ,115.9206 ,170.5576 ,8.5084 ,139.1606 ,151.5307 ,67.6941 ,39.1542 ,323.9347 ,183.6418 ,75.2728 ,218.0335 ,294.1343 ,
      		7.4945 ,6.4312 ,52.7262 ,258.7808 ,57.6819 ,253.6580 ,244.1433 ,196.0928 ,79.4159 ,351.2140 ,287.2119 ,185.9758 ,80.3505 ,233.4623 ,142.1633 ,207.3045 ,115.6485 ,227.1412 ,21.1626 ,107.4981 ,348.4452 ,315.1923 ,110.2992 ,309.0652 ,111.7309 ,338.1438 ,267.7832 ,149.8220 ,90.8489 ,3.0529 ,316.3384 ,13.6500 ,294.9891 ,346.3924 ,205.3010 ,61.7462 ,312.4012 ,350.5591 ,253.4483 ,183.1945 ,136.0688 ,124.8951 ,74.0742 ,242.6951 ,155.8620 ,69.8827 ,37.5927 ,239.7447 ,106.5862 ,179.9280 ,
      		117.1244 ,313.7837 ,323.8842 ,6.5135 ,72.3071 ,117.9867 ,355.3379 ,281.7721 ,122.0744 ,76.6907 ,242.8038 ,301.5724 ,335.5875 ,123.7859 ,317.6616 ,247.3597 ,174.4195 ,354.7830 ,84.4706 ,261.1675 ,30.4849 ,61.0899 ,327.9556 ,76.6686 ,273.2818 ,216.0752 ,302.8076 ,132.5189 ,122.5027 ,104.8375 ,312.2711 ,217.4337 ,343.5507 ,319.4154 ,48.7246 ,198.4214 ,37.5390 ,14.0896 ,26.3496 ,311.8206 ,283.7219 ,298.2621 ,122.7231 ,221.4670 ,281.4853 ,136.0943 ,205.4813 ,80.5371 ,29.4276 ,96.0205 ,
      		320.6765 ,203.2009 ,333.0242 ,164.7969 ,99.7858 ,283.3253 ,297.9965 ,4.4574 ,241.3482 ,33.0059 ,41.4369 ,318.6216 ,14.4085 ,86.2680 ,355.7371 ,151.5649 ,41.6009 ,60.2580 ,86.9113 ,267.8423 ,37.0203 ,327.8752 ,136.1798 ,349.2951 ,327.3202 ,105.8485 ,91.2276 ,171.7236 ,36.0465 ,234.7381 ,14.2633 ,3.7822 ,353.7301 ,106.3979 ,214.7654 ,161.9440 ,112.7811 ,22.6673 ,328.8211 ,349.1328 ,349.1267 ,40.0904 ,77.4696 ,222.4105 ,352.7830 ,195.4488 ,247.7483 ,238.2604 ,93.2710 ,194.9768 ,
      		110.6356 ,88.6972 ,29.2928 ,101.0832 ,354.0156 ,161.2448 ,234.7238 ,231.6478 ,338.6644 ,140.5723 ,110.4423 ,117.8069 ,114.0247 ,304.9685 ,321.6601 ,109.0114 ,120.3600 ,195.9211 ,208.4348 ,214.5465 ,88.2353 ,7.3347 ,87.7533 ,26.0379 ,198.4337 ,25.5299 ,27.0467 ,228.7376 ,104.6958 ,285.1865 ,177.5740 ,310.5536 ,55.5047 ,180.5147 ,286.1941 ,27.7585 ,341.7221 ,62.3672 ,279.4352 ,354.5625 ,295.7581 ,115.1222 ,38.4760 ,185.1690 ,330.9685 ,105.6562 ,321.7532 ,51.0050 ,327.7734 ,11.4336 ,
      		113.7847 ,325.1118 ,289.3883 ,326.5754 ,302.6587 ,268.6266 ,248.2543 ,64.1358 ,155.7497 ,56.8429 ,257.3368 ,240.4003 ,90.9311 ,23.1891 ,346.8189 ,290.9709 ,197.7372 ,194.8960 ,306.4654 ,163.1915 ,142.4558 ,121.9209 ,92.8689 ,8.7871 ,232.7180 ,150.0062 ,205.4173 ,22.4358 ,127.7796 ,49.7823 ,45.0464 ,93.2807 ,298.4164 ,143.2070 ,144.3896 ,220.4802 ,84.0707 ,2.6918 ,190.3326 ,180.3239 ,233.5823 ,157.7941 ,247.1447 ,263.3119 ,85.8149 ,178.2260 ,172.3777 ,81.0224 ,148.4086 ,201.7467 ,
      		326.4982 ,330.3744 ,99.0811 ,232.7095 ,17.3510 ,25.7585 ,184.2090 ,315.8727 ,57.4084 ,275.7700 ,317.8834 ,112.2487 ,249.3205 ,305.6368 ,133.7812 ,252.4618 ,265.1105 ,214.0480 ,308.2598 ,322.7776 ,345.6284 ,205.6438 ,63.4593 ,90.2143 ,78.3427 ,205.0262 ,272.7900 ,18.7680 ,245.3891 ,258.1752 ,125.2733 ,185.4201 ,59.3273 ,262.7626 ,14.6551 ,353.2396 ,290.8597 ,226.2415 ,96.3094 ,328.6306 ,345.3980 ,50.0854 ,279.2726 ,303.0951 ,237.4982 ,252.1468 ,160.2211 ,332.7508 ,349.6347 ,137.6472 ,
      		288.9762 ,155.8518 ,59.3115 ,117.1682 ,45.4788 ,327.1985 ,345.3927 ,42.9072 ,216.2445 ,146.9607 ,42.5124 ,106.3712 ,89.3579 ,269.8477 ,1.4432 ,68.3419 ,157.9583 ,7.5725 ,225.9096 ,218.0259 ,300.7196 ,74.3781 ,102.5214 ,195.2422 ,98.3613 ,210.8657 ,90.3176 ,246.0698 ,284.7927 ,291.1157 ,350.5018 ,196.3357 ,176.6913 ,308.0512 ,276.8643 ,205.3961 ,137.9723 ,102.2571 ,38.9301 ,290.7177 ,42.5058 ,269.0155 ,196.3034 ,347.3803 ,273.9836 ,350.4671 ,49.1738 ,180.1337 ,206.1282 ,112.0505 ,
      		181.0917 ,128.4548 ,190.2218 ,0.3041 ,159.2332 ,161.8388 ,109.7277 ,143.7850 ,281.9114 ,246.0286 ,177.2277 ,233.1606 ,135.9210 ,73.4091 ,1.3952 ,99.9437 ,215.3391 ,317.3987 ,298.5916 ,183.9457 ,355.3265 ,166.1692 ,300.4537 ,147.2275 ,268.0670 ,355.5330 ,109.9212 ,61.3126 ,223.2121 ,191.1442 ,129.3919 ,1.2669 ,140.0986 ,153.3130 ,145.8907 ,310.0483 ,210.3941 ,264.1791 ,323.2473 ,269.5584 ,177.3727 ,268.4766 ,230.5279 ,233.5484 ,226.6831 ,146.5196 ,226.5343 ,228.1437 ,337.3625 ,281.6905 ,
      		304.6565 ,276.2999 ,293.5173 ,217.9665 ,125.8020 ,95.2500 ,254.8872 ,314.6191 ,195.9288 ,54.7452 ,299.8711 ,174.4355 ,168.1569 ,16.3397 ,183.7011 ,268.1092 ,152.1352 ,127.8638 ,236.4637 ,7.1069 ,182.5789 ,340.6058 ,248.5611 ,144.6925 ,248.0070 ,217.7978 ,75.2002 ,74.7750 ,318.9691 ,96.8649 ,26.9585 ,299.0439 ,188.3512 ,132.5549 ,184.1468 ,265.2212 ,60.6793 ,235.1041 ,256.8373 ,293.4012 ,97.1138 ,219.4799 ,83.5610 ,201.9761 ,62.0507 ,284.3163 ,312.0184 ,118.6717 ,80.0347 ,346.9638 ,
      		254.4085 ,303.7653 ,10.9924 ,323.7816 ,224.0827 ,113.9505 ,155.4356 ,274.1735 ,282.7483 ,68.3643 ,225.3191 ,59.6266 ,350.2979 ,159.6876 ,328.7322 ,262.1692 ,218.2536 ,94.3143 ,189.5732 ,49.9031 ,49.7153 ,257.6699 ,129.9923 ,270.4955 ,86.5777 ,258.5369 ,258.6517 ,109.9785 ,38.2988 ,142.9228 ,177.2501 ,35.9907 ,67.2341 ,19.9235 ,215.1049 ,319.9954 ,77.9608 ,12.4968 ,253.4125 ,293.3678 ,347.0838 ,220.7444 ,123.2795 ,301.6327 ,42.5042 ,249.3493 ,34.2831 ,143.8941 ,178.2082 ,136.0419 ,
      		60.6951 ,83.4182 ,295.2540 ,166.5273 ,208.7758 ,76.2865 ,257.3766 ,118.8422 ,213.7027 ,327.4153 ,357.9816 ,16.6385 ,287.0794 ,308.7316 ,115.0468 ,137.9331 ,208.8914 ,330.7825 ,143.9743 ,316.8109 ,273.0818 ,54.8183 ,328.9248 ,5.4652 ,52.2642 ,239.3320 ,20.5631 ,136.6164 ,46.7924 ,166.6401 ,302.3929 ,326.1904 ,12.7691 ,21.9066 ,302.6247 ,15.4133 ,98.4925 ,42.2772 ,32.7736 ,9.9442 ,229.5047 ,268.0611 ,247.2377 ,304.4242 ,238.6858 ,140.2927 ,227.1827 ,349.0541 ,230.9772 ,87.5130 ,
      		21.6663 ,336.6598 ,212.5784 ,125.8613 ,217.9270 ,201.6927 ,187.9818 ,21.8897 ,127.1619 ,148.5540 ,71.7726 ,316.8379 ,152.6831 ,238.4588 ,256.8767 ,267.5819 ,259.6015 ,270.7951 ,90.5690 ,351.5053 ,54.3635 ,330.7131 ,307.6448 ,306.7791 ,19.0121 ,32.8385 ,292.7001 ,168.9001 ,133.2911 ,354.4875 ,14.4425 ,191.3274 ,159.6059 ,46.1531 ,142.2678 ,254.7531 ,317.6336 ,8.8631 ,188.8234 ,32.5356 ,288.1416 ,30.8827 ,12.3096 ,138.3250 ,263.7382 ,112.7544 ,46.8018 ,286.0460 ,290.4910 ,308.1095};
#endif

#ifdef INPUT_ARRAY_SIZE_1000
#ifdef INPUT_DATA_IN_CCM
   __attribute__((section(".ccmramdata")))
#endif
      float arr_input[1000] ={48.3711 ,305.0761 ,274.9589 ,91.8248 ,178.3566 ,161.8168 ,234.5735 ,283.9404 ,33.7895 ,10.2051 ,300.8754 ,155.7961 ,274.4208 ,0.7582 ,160.3394 ,259.7544 ,82.3544 ,340.2975 ,324.5139 ,11.0124 ,9.1605 ,194.9085 ,338.0937 ,137.2335 ,77.9758 ,151.9620 ,10.4547 ,79.8090 ,157.6395 ,178.4924 ,83.9104 ,83.1120 ,78.7612 ,165.4572 ,104.3214 ,7.7363 ,301.5281 ,200.3236 ,231.2260 ,66.9263 ,357.3156 ,309.5808 ,43.5204 ,119.7703 ,259.7344 ,256.0290 ,337.1186 ,151.9585 ,298.8128 ,241.3100 ,
      		109.2127 ,211.5290 ,317.6924 ,304.6311 ,181.9022 ,212.0408 ,12.4293 ,87.3864 ,287.0655 ,149.1530 ,62.2827 ,197.5676 ,253.0947 ,242.8149 ,134.8931 ,158.0262 ,183.0335 ,280.2393 ,187.5378 ,141.5718 ,176.2897 ,10.6470 ,15.6554 ,253.2176 ,353.9476 ,213.5461 ,141.6959 ,61.3257 ,180.8059 ,353.5476 ,277.3883 ,194.2623 ,309.7043 ,83.5834 ,184.9578 ,342.8883 ,208.0061 ,165.2874 ,96.9406 ,197.2787 ,344.5619 ,2.0553 ,282.1159 ,295.3749 ,319.0246 ,266.5812 ,291.2904 ,186.7242 ,202.0888 ,153.3926 ,
      		20.2044 ,313.2037 ,205.1998 ,71.9422 ,181.6994 ,174.5730 ,128.4444 ,124.5881 ,193.8524 ,224.4562 ,220.4829 ,164.9328 ,10.0710 ,82.6578 ,63.7961 ,210.4059 ,309.9632 ,287.4380 ,286.9551 ,293.9175 ,91.9059 ,303.0281 ,242.3209 ,29.9643 ,6.0086 ,5.2416 ,272.0112 ,89.8413 ,39.4159 ,224.9288 ,123.9922 ,25.0255 ,57.4652 ,189.8569 ,60.5322 ,98.2492 ,256.1724 ,163.6926 ,115.9206 ,170.5576 ,8.5084 ,139.1606 ,151.5307 ,67.6941 ,39.1542 ,323.9347 ,183.6418 ,75.2728 ,218.0335 ,294.1343 ,
      		7.4945 ,6.4312 ,52.7262 ,258.7808 ,57.6819 ,253.6580 ,244.1433 ,196.0928 ,79.4159 ,351.2140 ,287.2119 ,185.9758 ,80.3505 ,233.4623 ,142.1633 ,207.3045 ,115.6485 ,227.1412 ,21.1626 ,107.4981 ,348.4452 ,315.1923 ,110.2992 ,309.0652 ,111.7309 ,338.1438 ,267.7832 ,149.8220 ,90.8489 ,3.0529 ,316.3384 ,13.6500 ,294.9891 ,346.3924 ,205.3010 ,61.7462 ,312.4012 ,350.5591 ,253.4483 ,183.1945 ,136.0688 ,124.8951 ,74.0742 ,242.6951 ,155.8620 ,69.8827 ,37.5927 ,239.7447 ,106.5862 ,179.9280 ,
      		117.1244 ,313.7837 ,323.8842 ,6.5135 ,72.3071 ,117.9867 ,355.3379 ,281.7721 ,122.0744 ,76.6907 ,242.8038 ,301.5724 ,335.5875 ,123.7859 ,317.6616 ,247.3597 ,174.4195 ,354.7830 ,84.4706 ,261.1675 ,30.4849 ,61.0899 ,327.9556 ,76.6686 ,273.2818 ,216.0752 ,302.8076 ,132.5189 ,122.5027 ,104.8375 ,312.2711 ,217.4337 ,343.5507 ,319.4154 ,48.7246 ,198.4214 ,37.5390 ,14.0896 ,26.3496 ,311.8206 ,283.7219 ,298.2621 ,122.7231 ,221.4670 ,281.4853 ,136.0943 ,205.4813 ,80.5371 ,29.4276 ,96.0205 ,
      		320.6765 ,203.2009 ,333.0242 ,164.7969 ,99.7858 ,283.3253 ,297.9965 ,4.4574 ,241.3482 ,33.0059 ,41.4369 ,318.6216 ,14.4085 ,86.2680 ,355.7371 ,151.5649 ,41.6009 ,60.2580 ,86.9113 ,267.8423 ,37.0203 ,327.8752 ,136.1798 ,349.2951 ,327.3202 ,105.8485 ,91.2276 ,171.7236 ,36.0465 ,234.7381 ,14.2633 ,3.7822 ,353.7301 ,106.3979 ,214.7654 ,161.9440 ,112.7811 ,22.6673 ,328.8211 ,349.1328 ,349.1267 ,40.0904 ,77.4696 ,222.4105 ,352.7830 ,195.4488 ,247.7483 ,238.2604 ,93.2710 ,194.9768 ,
      		110.6356 ,88.6972 ,29.2928 ,101.0832 ,354.0156 ,161.2448 ,234.7238 ,231.6478 ,338.6644 ,140.5723 ,110.4423 ,117.8069 ,114.0247 ,304.9685 ,321.6601 ,109.0114 ,120.3600 ,195.9211 ,208.4348 ,214.5465 ,88.2353 ,7.3347 ,87.7533 ,26.0379 ,198.4337 ,25.5299 ,27.0467 ,228.7376 ,104.6958 ,285.1865 ,177.5740 ,310.5536 ,55.5047 ,180.5147 ,286.1941 ,27.7585 ,341.7221 ,62.3672 ,279.4352 ,354.5625 ,295.7581 ,115.1222 ,38.4760 ,185.1690 ,330.9685 ,105.6562 ,321.7532 ,51.0050 ,327.7734 ,11.4336 ,
      		113.7847 ,325.1118 ,289.3883 ,326.5754 ,302.6587 ,268.6266 ,248.2543 ,64.1358 ,155.7497 ,56.8429 ,257.3368 ,240.4003 ,90.9311 ,23.1891 ,346.8189 ,290.9709 ,197.7372 ,194.8960 ,306.4654 ,163.1915 ,142.4558 ,121.9209 ,92.8689 ,8.7871 ,232.7180 ,150.0062 ,205.4173 ,22.4358 ,127.7796 ,49.7823 ,45.0464 ,93.2807 ,298.4164 ,143.2070 ,144.3896 ,220.4802 ,84.0707 ,2.6918 ,190.3326 ,180.3239 ,233.5823 ,157.7941 ,247.1447 ,263.3119 ,85.8149 ,178.2260 ,172.3777 ,81.0224 ,148.4086 ,201.7467 ,
      		326.4982 ,330.3744 ,99.0811 ,232.7095 ,17.3510 ,25.7585 ,184.2090 ,315.8727 ,57.4084 ,275.7700 ,317.8834 ,112.2487 ,249.3205 ,305.6368 ,133.7812 ,252.4618 ,265.1105 ,214.0480 ,308.2598 ,322.7776 ,345.6284 ,205.6438 ,63.4593 ,90.2143 ,78.3427 ,205.0262 ,272.7900 ,18.7680 ,245.3891 ,258.1752 ,125.2733 ,185.4201 ,59.3273 ,262.7626 ,14.6551 ,353.2396 ,290.8597 ,226.2415 ,96.3094 ,328.6306 ,345.3980 ,50.0854 ,279.2726 ,303.0951 ,237.4982 ,252.1468 ,160.2211 ,332.7508 ,349.6347 ,137.6472 ,
      		288.9762 ,155.8518 ,59.3115 ,117.1682 ,45.4788 ,327.1985 ,345.3927 ,42.9072 ,216.2445 ,146.9607 ,42.5124 ,106.3712 ,89.3579 ,269.8477 ,1.4432 ,68.3419 ,157.9583 ,7.5725 ,225.9096 ,218.0259 ,300.7196 ,74.3781 ,102.5214 ,195.2422 ,98.3613 ,210.8657 ,90.3176 ,246.0698 ,284.7927 ,291.1157 ,350.5018 ,196.3357 ,176.6913 ,308.0512 ,276.8643 ,205.3961 ,137.9723 ,102.2571 ,38.9301 ,290.7177 ,42.5058 ,269.0155 ,196.3034 ,347.3803 ,273.9836 ,350.4671 ,49.1738 ,180.1337 ,206.1282 ,112.0505 ,
      		181.0917 ,128.4548 ,190.2218 ,0.3041 ,159.2332 ,161.8388 ,109.7277 ,143.7850 ,281.9114 ,246.0286 ,177.2277 ,233.1606 ,135.9210 ,73.4091 ,1.3952 ,99.9437 ,215.3391 ,317.3987 ,298.5916 ,183.9457 ,355.3265 ,166.1692 ,300.4537 ,147.2275 ,268.0670 ,355.5330 ,109.9212 ,61.3126 ,223.2121 ,191.1442 ,129.3919 ,1.2669 ,140.0986 ,153.3130 ,145.8907 ,310.0483 ,210.3941 ,264.1791 ,323.2473 ,269.5584 ,177.3727 ,268.4766 ,230.5279 ,233.5484 ,226.6831 ,146.5196 ,226.5343 ,228.1437 ,337.3625 ,281.6905 ,
      		304.6565 ,276.2999 ,293.5173 ,217.9665 ,125.8020 ,95.2500 ,254.8872 ,314.6191 ,195.9288 ,54.7452 ,299.8711 ,174.4355 ,168.1569 ,16.3397 ,183.7011 ,268.1092 ,152.1352 ,127.8638 ,236.4637 ,7.1069 ,182.5789 ,340.6058 ,248.5611 ,144.6925 ,248.0070 ,217.7978 ,75.2002 ,74.7750 ,318.9691 ,96.8649 ,26.9585 ,299.0439 ,188.3512 ,132.5549 ,184.1468 ,265.2212 ,60.6793 ,235.1041 ,256.8373 ,293.4012 ,97.1138 ,219.4799 ,83.5610 ,201.9761 ,62.0507 ,284.3163 ,312.0184 ,118.6717 ,80.0347 ,346.9638 ,
      		254.4085 ,303.7653 ,10.9924 ,323.7816 ,224.0827 ,113.9505 ,155.4356 ,274.1735 ,282.7483 ,68.3643 ,225.3191 ,59.6266 ,350.2979 ,159.6876 ,328.7322 ,262.1692 ,218.2536 ,94.3143 ,189.5732 ,49.9031 ,49.7153 ,257.6699 ,129.9923 ,270.4955 ,86.5777 ,258.5369 ,258.6517 ,109.9785 ,38.2988 ,142.9228 ,177.2501 ,35.9907 ,67.2341 ,19.9235 ,215.1049 ,319.9954 ,77.9608 ,12.4968 ,253.4125 ,293.3678 ,347.0838 ,220.7444 ,123.2795 ,301.6327 ,42.5042 ,249.3493 ,34.2831 ,143.8941 ,178.2082 ,136.0419 ,
      		60.6951 ,83.4182 ,295.2540 ,166.5273 ,208.7758 ,76.2865 ,257.3766 ,118.8422 ,213.7027 ,327.4153 ,357.9816 ,16.6385 ,287.0794 ,308.7316 ,115.0468 ,137.9331 ,208.8914 ,330.7825 ,143.9743 ,316.8109 ,273.0818 ,54.8183 ,328.9248 ,5.4652 ,52.2642 ,239.3320 ,20.5631 ,136.6164 ,46.7924 ,166.6401 ,302.3929 ,326.1904 ,12.7691 ,21.9066 ,302.6247 ,15.4133 ,98.4925 ,42.2772 ,32.7736 ,9.9442 ,229.5047 ,268.0611 ,247.2377 ,304.4242 ,238.6858 ,140.2927 ,227.1827 ,349.0541 ,230.9772 ,87.5130 ,
      		21.6663 ,336.6598 ,212.5784 ,125.8613 ,217.9270 ,201.6927 ,187.9818 ,21.8897 ,127.1619 ,148.5540 ,71.7726 ,316.8379 ,152.6831 ,238.4588 ,256.8767 ,267.5819 ,259.6015 ,270.7951 ,90.5690 ,351.5053 ,54.3635 ,330.7131 ,307.6448 ,306.7791 ,19.0121 ,32.8385 ,292.7001 ,168.9001 ,133.2911 ,354.4875 ,14.4425 ,191.3274 ,159.6059 ,46.1531 ,142.2678 ,254.7531 ,317.6336 ,8.8631 ,188.8234 ,32.5356 ,288.1416 ,30.8827 ,12.3096 ,138.3250 ,263.7382 ,112.7544 ,46.8018 ,286.0460 ,290.4910 ,308.1095 ,
      		109.3480 ,152.9389 ,88.3404 ,200.5839 ,118.8386 ,121.9188 ,282.1037 ,344.2666 ,210.2905 ,37.6877 ,234.9270 ,161.5002 ,355.6910 ,258.9773 ,300.5230 ,252.4631 ,192.8228 ,322.8546 ,299.3821 ,104.8773 ,56.5315 ,133.3267 ,187.5880 ,35.0568 ,124.3365 ,206.9660 ,15.6869 ,293.3815 ,234.4021 ,112.9141 ,107.3956 ,126.9418 ,117.1039 ,269.4650 ,180.3805 ,189.4062 ,53.5523 ,329.1905 ,117.2063 ,117.9232 ,24.7846 ,352.5882 ,172.6912 ,328.6385 ,333.9422 ,349.1108 ,293.6265 ,333.1596 ,332.0242 ,288.4924 ,
      		48.4492 ,188.5362 ,207.2174 ,357.2991 ,282.2215 ,253.0498 ,268.7937 ,130.1680 ,339.2329 ,231.6603 ,144.9269 ,167.2458 ,352.7118 ,191.5662 ,60.4071 ,53.4078 ,247.4072 ,202.5992 ,326.4503 ,66.4561 ,147.9992 ,262.0657 ,18.0378 ,35.7201 ,196.4548 ,95.6625 ,38.4975 ,94.2111 ,227.5708 ,189.4959 ,28.2588 ,26.2121 ,306.2257 ,231.5660 ,62.4122 ,310.2603 ,7.8658 ,132.5177 ,305.1467 ,255.7002 ,102.1509 ,320.8613 ,215.3081 ,311.5776 ,321.4056 ,153.1599 ,243.2161 ,196.0115 ,340.1047 ,287.3379 ,
      		261.2947 ,293.0517 ,359.3376 ,92.3620 ,72.4909 ,268.8418 ,277.3197 ,185.1422 ,175.3473 ,145.3475 ,317.7709 ,286.6435 ,210.4551 ,14.4429 ,306.4110 ,165.0433 ,68.3138 ,107.7675 ,248.8804 ,1.9825 ,43.2161 ,108.9553 ,319.3889 ,268.8698 ,349.4850 ,195.4903 ,205.9086 ,198.4957 ,189.2258 ,195.1346 ,294.6843 ,343.2127 ,146.9883 ,226.7875 ,110.7934 ,108.6877 ,182.2742 ,211.0564 ,197.9980 ,351.5687 ,58.6696 ,229.1992 ,358.0312 ,265.0087 ,203.7271 ,132.6107 ,144.7700 ,337.1483 ,322.3190 ,241.0835 ,
      		323.5492 ,333.0589 ,304.6837 ,138.0298 ,167.1713 ,286.5267 ,134.1479 ,269.7710 ,173.3113 ,121.1549 ,164.2134 ,41.9434 ,127.6188 ,149.4700 ,6.5389 ,61.9466 ,93.6839 ,308.8383 ,212.2478 ,103.3722 ,359.1816 ,92.8514 ,184.9638 ,266.2271 ,248.8754 ,156.0610 ,279.7192 ,174.8859 ,257.5674 ,176.8956 ,349.7381 ,257.8248 ,32.8958 ,46.6092 ,347.9453 ,82.5222 ,9.4090 ,91.1605 ,172.7233 ,342.7807 ,143.6868 ,260.4620 ,300.3705 ,32.0983 ,220.2811 ,358.4824 ,197.8545 ,192.4150 ,124.8129 ,340.5979 ,
      		349.0557 ,37.1411 ,199.0202 ,151.0665 ,241.7926 ,42.7128 ,95.5203 ,100.3512 ,172.6967 ,285.5818 ,308.8251 ,283.1125 ,243.6505 ,31.3894 ,140.2981 ,240.7326 ,105.9292 ,182.8146 ,325.8282 ,41.8165 ,307.3956 ,38.0987 ,139.0912 ,325.9402 ,72.4320 ,187.4673 ,149.9775 ,319.6610 ,357.1433 ,103.8933 ,177.2916 ,322.2019 ,196.1264 ,77.2650 ,273.4784 ,121.3521 ,174.9508 ,3.0823 ,356.0281 ,236.6217 ,333.2926 ,348.7267 ,96.3121 ,194.5930 ,158.4904 ,273.5479 ,303.2588 ,82.2817 ,98.8433 ,254.2542};
#endif

#ifdef INPUT_ARRAY_SIZE_1250
#ifdef INPUT_DATA_IN_CCM
   __attribute__((section(".ccmramdata")))
#endif
   float arr_input[1250] ={48.3711 ,305.0761 ,274.9589 ,91.8248 ,178.3566 ,161.8168 ,234.5735 ,283.9404 ,33.7895 ,10.2051 ,300.8754 ,155.7961 ,274.4208 ,0.7582 ,160.3394 ,259.7544 ,82.3544 ,340.2975 ,324.5139 ,11.0124 ,9.1605 ,194.9085 ,338.0937 ,137.2335 ,77.9758 ,151.9620 ,10.4547 ,79.8090 ,157.6395 ,178.4924 ,83.9104 ,83.1120 ,78.7612 ,165.4572 ,104.3214 ,7.7363 ,301.5281 ,200.3236 ,231.2260 ,66.9263 ,357.3156 ,309.5808 ,43.5204 ,119.7703 ,259.7344 ,256.0290 ,337.1186 ,151.9585 ,298.8128 ,241.3100 ,
      		109.2127 ,211.5290 ,317.6924 ,304.6311 ,181.9022 ,212.0408 ,12.4293 ,87.3864 ,287.0655 ,149.1530 ,62.2827 ,197.5676 ,253.0947 ,242.8149 ,134.8931 ,158.0262 ,183.0335 ,280.2393 ,187.5378 ,141.5718 ,176.2897 ,10.6470 ,15.6554 ,253.2176 ,353.9476 ,213.5461 ,141.6959 ,61.3257 ,180.8059 ,353.5476 ,277.3883 ,194.2623 ,309.7043 ,83.5834 ,184.9578 ,342.8883 ,208.0061 ,165.2874 ,96.9406 ,197.2787 ,344.5619 ,2.0553 ,282.1159 ,295.3749 ,319.0246 ,266.5812 ,291.2904 ,186.7242 ,202.0888 ,153.3926 ,
      		20.2044 ,313.2037 ,205.1998 ,71.9422 ,181.6994 ,174.5730 ,128.4444 ,124.5881 ,193.8524 ,224.4562 ,220.4829 ,164.9328 ,10.0710 ,82.6578 ,63.7961 ,210.4059 ,309.9632 ,287.4380 ,286.9551 ,293.9175 ,91.9059 ,303.0281 ,242.3209 ,29.9643 ,6.0086 ,5.2416 ,272.0112 ,89.8413 ,39.4159 ,224.9288 ,123.9922 ,25.0255 ,57.4652 ,189.8569 ,60.5322 ,98.2492 ,256.1724 ,163.6926 ,115.9206 ,170.5576 ,8.5084 ,139.1606 ,151.5307 ,67.6941 ,39.1542 ,323.9347 ,183.6418 ,75.2728 ,218.0335 ,294.1343 ,
      		7.4945 ,6.4312 ,52.7262 ,258.7808 ,57.6819 ,253.6580 ,244.1433 ,196.0928 ,79.4159 ,351.2140 ,287.2119 ,185.9758 ,80.3505 ,233.4623 ,142.1633 ,207.3045 ,115.6485 ,227.1412 ,21.1626 ,107.4981 ,348.4452 ,315.1923 ,110.2992 ,309.0652 ,111.7309 ,338.1438 ,267.7832 ,149.8220 ,90.8489 ,3.0529 ,316.3384 ,13.6500 ,294.9891 ,346.3924 ,205.3010 ,61.7462 ,312.4012 ,350.5591 ,253.4483 ,183.1945 ,136.0688 ,124.8951 ,74.0742 ,242.6951 ,155.8620 ,69.8827 ,37.5927 ,239.7447 ,106.5862 ,179.9280 ,
      		117.1244 ,313.7837 ,323.8842 ,6.5135 ,72.3071 ,117.9867 ,355.3379 ,281.7721 ,122.0744 ,76.6907 ,242.8038 ,301.5724 ,335.5875 ,123.7859 ,317.6616 ,247.3597 ,174.4195 ,354.7830 ,84.4706 ,261.1675 ,30.4849 ,61.0899 ,327.9556 ,76.6686 ,273.2818 ,216.0752 ,302.8076 ,132.5189 ,122.5027 ,104.8375 ,312.2711 ,217.4337 ,343.5507 ,319.4154 ,48.7246 ,198.4214 ,37.5390 ,14.0896 ,26.3496 ,311.8206 ,283.7219 ,298.2621 ,122.7231 ,221.4670 ,281.4853 ,136.0943 ,205.4813 ,80.5371 ,29.4276 ,96.0205 ,
      		320.6765 ,203.2009 ,333.0242 ,164.7969 ,99.7858 ,283.3253 ,297.9965 ,4.4574 ,241.3482 ,33.0059 ,41.4369 ,318.6216 ,14.4085 ,86.2680 ,355.7371 ,151.5649 ,41.6009 ,60.2580 ,86.9113 ,267.8423 ,37.0203 ,327.8752 ,136.1798 ,349.2951 ,327.3202 ,105.8485 ,91.2276 ,171.7236 ,36.0465 ,234.7381 ,14.2633 ,3.7822 ,353.7301 ,106.3979 ,214.7654 ,161.9440 ,112.7811 ,22.6673 ,328.8211 ,349.1328 ,349.1267 ,40.0904 ,77.4696 ,222.4105 ,352.7830 ,195.4488 ,247.7483 ,238.2604 ,93.2710 ,194.9768 ,
      		110.6356 ,88.6972 ,29.2928 ,101.0832 ,354.0156 ,161.2448 ,234.7238 ,231.6478 ,338.6644 ,140.5723 ,110.4423 ,117.8069 ,114.0247 ,304.9685 ,321.6601 ,109.0114 ,120.3600 ,195.9211 ,208.4348 ,214.5465 ,88.2353 ,7.3347 ,87.7533 ,26.0379 ,198.4337 ,25.5299 ,27.0467 ,228.7376 ,104.6958 ,285.1865 ,177.5740 ,310.5536 ,55.5047 ,180.5147 ,286.1941 ,27.7585 ,341.7221 ,62.3672 ,279.4352 ,354.5625 ,295.7581 ,115.1222 ,38.4760 ,185.1690 ,330.9685 ,105.6562 ,321.7532 ,51.0050 ,327.7734 ,11.4336 ,
      		113.7847 ,325.1118 ,289.3883 ,326.5754 ,302.6587 ,268.6266 ,248.2543 ,64.1358 ,155.7497 ,56.8429 ,257.3368 ,240.4003 ,90.9311 ,23.1891 ,346.8189 ,290.9709 ,197.7372 ,194.8960 ,306.4654 ,163.1915 ,142.4558 ,121.9209 ,92.8689 ,8.7871 ,232.7180 ,150.0062 ,205.4173 ,22.4358 ,127.7796 ,49.7823 ,45.0464 ,93.2807 ,298.4164 ,143.2070 ,144.3896 ,220.4802 ,84.0707 ,2.6918 ,190.3326 ,180.3239 ,233.5823 ,157.7941 ,247.1447 ,263.3119 ,85.8149 ,178.2260 ,172.3777 ,81.0224 ,148.4086 ,201.7467 ,
      		326.4982 ,330.3744 ,99.0811 ,232.7095 ,17.3510 ,25.7585 ,184.2090 ,315.8727 ,57.4084 ,275.7700 ,317.8834 ,112.2487 ,249.3205 ,305.6368 ,133.7812 ,252.4618 ,265.1105 ,214.0480 ,308.2598 ,322.7776 ,345.6284 ,205.6438 ,63.4593 ,90.2143 ,78.3427 ,205.0262 ,272.7900 ,18.7680 ,245.3891 ,258.1752 ,125.2733 ,185.4201 ,59.3273 ,262.7626 ,14.6551 ,353.2396 ,290.8597 ,226.2415 ,96.3094 ,328.6306 ,345.3980 ,50.0854 ,279.2726 ,303.0951 ,237.4982 ,252.1468 ,160.2211 ,332.7508 ,349.6347 ,137.6472 ,
      		288.9762 ,155.8518 ,59.3115 ,117.1682 ,45.4788 ,327.1985 ,345.3927 ,42.9072 ,216.2445 ,146.9607 ,42.5124 ,106.3712 ,89.3579 ,269.8477 ,1.4432 ,68.3419 ,157.9583 ,7.5725 ,225.9096 ,218.0259 ,300.7196 ,74.3781 ,102.5214 ,195.2422 ,98.3613 ,210.8657 ,90.3176 ,246.0698 ,284.7927 ,291.1157 ,350.5018 ,196.3357 ,176.6913 ,308.0512 ,276.8643 ,205.3961 ,137.9723 ,102.2571 ,38.9301 ,290.7177 ,42.5058 ,269.0155 ,196.3034 ,347.3803 ,273.9836 ,350.4671 ,49.1738 ,180.1337 ,206.1282 ,112.0505 ,
      		181.0917 ,128.4548 ,190.2218 ,0.3041 ,159.2332 ,161.8388 ,109.7277 ,143.7850 ,281.9114 ,246.0286 ,177.2277 ,233.1606 ,135.9210 ,73.4091 ,1.3952 ,99.9437 ,215.3391 ,317.3987 ,298.5916 ,183.9457 ,355.3265 ,166.1692 ,300.4537 ,147.2275 ,268.0670 ,355.5330 ,109.9212 ,61.3126 ,223.2121 ,191.1442 ,129.3919 ,1.2669 ,140.0986 ,153.3130 ,145.8907 ,310.0483 ,210.3941 ,264.1791 ,323.2473 ,269.5584 ,177.3727 ,268.4766 ,230.5279 ,233.5484 ,226.6831 ,146.5196 ,226.5343 ,228.1437 ,337.3625 ,281.6905 ,
      		304.6565 ,276.2999 ,293.5173 ,217.9665 ,125.8020 ,95.2500 ,254.8872 ,314.6191 ,195.9288 ,54.7452 ,299.8711 ,174.4355 ,168.1569 ,16.3397 ,183.7011 ,268.1092 ,152.1352 ,127.8638 ,236.4637 ,7.1069 ,182.5789 ,340.6058 ,248.5611 ,144.6925 ,248.0070 ,217.7978 ,75.2002 ,74.7750 ,318.9691 ,96.8649 ,26.9585 ,299.0439 ,188.3512 ,132.5549 ,184.1468 ,265.2212 ,60.6793 ,235.1041 ,256.8373 ,293.4012 ,97.1138 ,219.4799 ,83.5610 ,201.9761 ,62.0507 ,284.3163 ,312.0184 ,118.6717 ,80.0347 ,346.9638 ,
      		254.4085 ,303.7653 ,10.9924 ,323.7816 ,224.0827 ,113.9505 ,155.4356 ,274.1735 ,282.7483 ,68.3643 ,225.3191 ,59.6266 ,350.2979 ,159.6876 ,328.7322 ,262.1692 ,218.2536 ,94.3143 ,189.5732 ,49.9031 ,49.7153 ,257.6699 ,129.9923 ,270.4955 ,86.5777 ,258.5369 ,258.6517 ,109.9785 ,38.2988 ,142.9228 ,177.2501 ,35.9907 ,67.2341 ,19.9235 ,215.1049 ,319.9954 ,77.9608 ,12.4968 ,253.4125 ,293.3678 ,347.0838 ,220.7444 ,123.2795 ,301.6327 ,42.5042 ,249.3493 ,34.2831 ,143.8941 ,178.2082 ,136.0419 ,
      		60.6951 ,83.4182 ,295.2540 ,166.5273 ,208.7758 ,76.2865 ,257.3766 ,118.8422 ,213.7027 ,327.4153 ,357.9816 ,16.6385 ,287.0794 ,308.7316 ,115.0468 ,137.9331 ,208.8914 ,330.7825 ,143.9743 ,316.8109 ,273.0818 ,54.8183 ,328.9248 ,5.4652 ,52.2642 ,239.3320 ,20.5631 ,136.6164 ,46.7924 ,166.6401 ,302.3929 ,326.1904 ,12.7691 ,21.9066 ,302.6247 ,15.4133 ,98.4925 ,42.2772 ,32.7736 ,9.9442 ,229.5047 ,268.0611 ,247.2377 ,304.4242 ,238.6858 ,140.2927 ,227.1827 ,349.0541 ,230.9772 ,87.5130 ,
      		21.6663 ,336.6598 ,212.5784 ,125.8613 ,217.9270 ,201.6927 ,187.9818 ,21.8897 ,127.1619 ,148.5540 ,71.7726 ,316.8379 ,152.6831 ,238.4588 ,256.8767 ,267.5819 ,259.6015 ,270.7951 ,90.5690 ,351.5053 ,54.3635 ,330.7131 ,307.6448 ,306.7791 ,19.0121 ,32.8385 ,292.7001 ,168.9001 ,133.2911 ,354.4875 ,14.4425 ,191.3274 ,159.6059 ,46.1531 ,142.2678 ,254.7531 ,317.6336 ,8.8631 ,188.8234 ,32.5356 ,288.1416 ,30.8827 ,12.3096 ,138.3250 ,263.7382 ,112.7544 ,46.8018 ,286.0460 ,290.4910 ,308.1095 ,
      		109.3480 ,152.9389 ,88.3404 ,200.5839 ,118.8386 ,121.9188 ,282.1037 ,344.2666 ,210.2905 ,37.6877 ,234.9270 ,161.5002 ,355.6910 ,258.9773 ,300.5230 ,252.4631 ,192.8228 ,322.8546 ,299.3821 ,104.8773 ,56.5315 ,133.3267 ,187.5880 ,35.0568 ,124.3365 ,206.9660 ,15.6869 ,293.3815 ,234.4021 ,112.9141 ,107.3956 ,126.9418 ,117.1039 ,269.4650 ,180.3805 ,189.4062 ,53.5523 ,329.1905 ,117.2063 ,117.9232 ,24.7846 ,352.5882 ,172.6912 ,328.6385 ,333.9422 ,349.1108 ,293.6265 ,333.1596 ,332.0242 ,288.4924 ,
      		48.4492 ,188.5362 ,207.2174 ,357.2991 ,282.2215 ,253.0498 ,268.7937 ,130.1680 ,339.2329 ,231.6603 ,144.9269 ,167.2458 ,352.7118 ,191.5662 ,60.4071 ,53.4078 ,247.4072 ,202.5992 ,326.4503 ,66.4561 ,147.9992 ,262.0657 ,18.0378 ,35.7201 ,196.4548 ,95.6625 ,38.4975 ,94.2111 ,227.5708 ,189.4959 ,28.2588 ,26.2121 ,306.2257 ,231.5660 ,62.4122 ,310.2603 ,7.8658 ,132.5177 ,305.1467 ,255.7002 ,102.1509 ,320.8613 ,215.3081 ,311.5776 ,321.4056 ,153.1599 ,243.2161 ,196.0115 ,340.1047 ,287.3379 ,
      		261.2947 ,293.0517 ,359.3376 ,92.3620 ,72.4909 ,268.8418 ,277.3197 ,185.1422 ,175.3473 ,145.3475 ,317.7709 ,286.6435 ,210.4551 ,14.4429 ,306.4110 ,165.0433 ,68.3138 ,107.7675 ,248.8804 ,1.9825 ,43.2161 ,108.9553 ,319.3889 ,268.8698 ,349.4850 ,195.4903 ,205.9086 ,198.4957 ,189.2258 ,195.1346 ,294.6843 ,343.2127 ,146.9883 ,226.7875 ,110.7934 ,108.6877 ,182.2742 ,211.0564 ,197.9980 ,351.5687 ,58.6696 ,229.1992 ,358.0312 ,265.0087 ,203.7271 ,132.6107 ,144.7700 ,337.1483 ,322.3190 ,241.0835 ,
      		323.5492 ,333.0589 ,304.6837 ,138.0298 ,167.1713 ,286.5267 ,134.1479 ,269.7710 ,173.3113 ,121.1549 ,164.2134 ,41.9434 ,127.6188 ,149.4700 ,6.5389 ,61.9466 ,93.6839 ,308.8383 ,212.2478 ,103.3722 ,359.1816 ,92.8514 ,184.9638 ,266.2271 ,248.8754 ,156.0610 ,279.7192 ,174.8859 ,257.5674 ,176.8956 ,349.7381 ,257.8248 ,32.8958 ,46.6092 ,347.9453 ,82.5222 ,9.4090 ,91.1605 ,172.7233 ,342.7807 ,143.6868 ,260.4620 ,300.3705 ,32.0983 ,220.2811 ,358.4824 ,197.8545 ,192.4150 ,124.8129 ,340.5979 ,
      		349.0557 ,37.1411 ,199.0202 ,151.0665 ,241.7926 ,42.7128 ,95.5203 ,100.3512 ,172.6967 ,285.5818 ,308.8251 ,283.1125 ,243.6505 ,31.3894 ,140.2981 ,240.7326 ,105.9292 ,182.8146 ,325.8282 ,41.8165 ,307.3956 ,38.0987 ,139.0912 ,325.9402 ,72.4320 ,187.4673 ,149.9775 ,319.6610 ,357.1433 ,103.8933 ,177.2916 ,322.2019 ,196.1264 ,77.2650 ,273.4784 ,121.3521 ,174.9508 ,3.0823 ,356.0281 ,236.6217 ,333.2926 ,348.7267 ,96.3121 ,194.5930 ,158.4904 ,273.5479 ,303.2588 ,82.2817 ,98.8433 ,254.2542 ,
      		148.1915 ,46.8726 ,70.3118 ,201.9058 ,215.4580 ,345.6258 ,191.8008 ,219.2331 ,53.5877 ,148.9687 ,100.7249 ,250.3522 ,96.1406 ,77.1841 ,132.3664 ,169.3977 ,121.8222 ,218.0636 ,65.2333 ,316.7677 ,249.9017 ,192.5148 ,20.9384 ,117.3624 ,248.4387 ,232.2231 ,292.3035 ,320.9431 ,113.5319 ,177.7430 ,118.8150 ,46.0520 ,50.4422 ,92.3290 ,31.6904 ,193.9772 ,253.0521 ,202.7061 ,246.5160 ,81.4493 ,71.7856 ,204.3269 ,318.3428 ,152.0152 ,1.5252 ,7.2186 ,109.9097 ,221.5347 ,30.4436 ,80.8237 ,
      		245.0486 ,354.5971 ,122.7862 ,216.4100 ,186.6347 ,8.3249 ,118.7404 ,50.1988 ,90.2958 ,277.1932 ,245.2329 ,14.7683 ,27.8550 ,260.9745 ,37.1555 ,114.1272 ,96.9615 ,17.9159 ,11.2212 ,50.0525 ,143.7578 ,336.1341 ,229.8161 ,87.1420 ,244.6719 ,98.5079 ,185.4857 ,115.8580 ,341.5215 ,126.8505 ,289.2826 ,230.8295 ,303.5972 ,218.2177 ,313.3386 ,145.8587 ,244.4410 ,223.4294 ,189.9841 ,203.1984 ,192.8743 ,141.7575 ,323.3950 ,227.7826 ,197.6843 ,19.4181 ,183.0701 ,63.0528 ,77.4084 ,156.4604 ,
      		196.5445 ,90.1484 ,97.5364 ,190.8527 ,170.3643 ,145.1835 ,37.3513 ,134.4520 ,235.5917 ,195.9116 ,196.1110 ,303.7745 ,260.3387 ,246.4521 ,10.9489 ,110.9261 ,245.6684 ,56.0782 ,328.8503 ,51.0936 ,316.4837 ,77.8566 ,302.9723 ,305.3627 ,120.7673 ,319.8933 ,57.5164 ,305.6794 ,137.4244 ,158.2983 ,42.4295 ,216.3619 ,97.1121 ,240.0765 ,287.7797 ,217.3262 ,2.9465 ,342.8407 ,331.0852 ,231.4567 ,136.6223 ,202.2890 ,317.8123 ,165.4304 ,280.5186 ,215.4812 ,152.0205 ,336.0696 ,147.0351 ,218.0805 ,
      		19.1787 ,169.4750 ,13.4691 ,253.4878 ,0.2125 ,15.1436 ,40.0052 ,50.2470 ,182.9082 ,128.2638 ,97.5252 ,354.1045 ,327.2400 ,235.7504 ,288.7513 ,295.0950 ,88.2624 ,290.9830 ,86.3322 ,202.4484 ,128.7781 ,57.1173 ,279.6676 ,329.8830 ,112.9315 ,316.7145 ,124.6522 ,236.7199 ,358.4843 ,277.9455 ,20.0402 ,156.5542 ,135.4692 ,105.8154 ,293.8088 ,158.7673 ,251.7265 ,228.5752 ,186.8385 ,20.1712 ,242.2927 ,320.8979 ,61.9918 ,231.3880 ,175.4782 ,122.7544 ,255.7536 ,351.0716 ,7.7993 ,323.0301 ,
      		137.9659 ,300.1854 ,62.8961 ,257.9730 ,35.8907 ,120.8197 ,349.1671 ,236.3816 ,282.4286 ,166.0700 ,169.6201 ,177.3451 ,278.3359 ,260.3699 ,69.7565 ,158.6176 ,195.1286 ,205.7143 ,333.6375 ,302.3090 ,53.9572 ,135.4035 ,39.2301 ,9.4406 ,26.8509 ,65.8676 ,275.7878 ,240.1997 ,287.2336 ,103.8612 ,55.9840 ,349.9561 ,297.3690 ,340.8415 ,6.7633 ,142.7571 ,228.1674 ,264.9868 ,328.5542 ,193.5834 ,140.6853 ,1.9166 ,289.3908 ,353.5769 ,326.6087 ,238.4167 ,123.2912 ,86.0941 ,279.0071 ,336.7546};
#endif

#ifdef INPUT_ARRAY_SIZE_1500
#ifdef INPUT_DATA_IN_CCM
   __attribute__((section(".ccmramdata")))
#endif
      float arr_input[1500] ={48.3711 ,305.0761 ,274.9589 ,91.8248 ,178.3566 ,161.8168 ,234.5735 ,283.9404 ,33.7895 ,10.2051 ,300.8754 ,155.7961 ,274.4208 ,0.7582 ,160.3394 ,259.7544 ,82.3544 ,340.2975 ,324.5139 ,11.0124 ,9.1605 ,194.9085 ,338.0937 ,137.2335 ,77.9758 ,151.9620 ,10.4547 ,79.8090 ,157.6395 ,178.4924 ,83.9104 ,83.1120 ,78.7612 ,165.4572 ,104.3214 ,7.7363 ,301.5281 ,200.3236 ,231.2260 ,66.9263 ,357.3156 ,309.5808 ,43.5204 ,119.7703 ,259.7344 ,256.0290 ,337.1186 ,151.9585 ,298.8128 ,241.3100 ,
      		109.2127 ,211.5290 ,317.6924 ,304.6311 ,181.9022 ,212.0408 ,12.4293 ,87.3864 ,287.0655 ,149.1530 ,62.2827 ,197.5676 ,253.0947 ,242.8149 ,134.8931 ,158.0262 ,183.0335 ,280.2393 ,187.5378 ,141.5718 ,176.2897 ,10.6470 ,15.6554 ,253.2176 ,353.9476 ,213.5461 ,141.6959 ,61.3257 ,180.8059 ,353.5476 ,277.3883 ,194.2623 ,309.7043 ,83.5834 ,184.9578 ,342.8883 ,208.0061 ,165.2874 ,96.9406 ,197.2787 ,344.5619 ,2.0553 ,282.1159 ,295.3749 ,319.0246 ,266.5812 ,291.2904 ,186.7242 ,202.0888 ,153.3926 ,
      		20.2044 ,313.2037 ,205.1998 ,71.9422 ,181.6994 ,174.5730 ,128.4444 ,124.5881 ,193.8524 ,224.4562 ,220.4829 ,164.9328 ,10.0710 ,82.6578 ,63.7961 ,210.4059 ,309.9632 ,287.4380 ,286.9551 ,293.9175 ,91.9059 ,303.0281 ,242.3209 ,29.9643 ,6.0086 ,5.2416 ,272.0112 ,89.8413 ,39.4159 ,224.9288 ,123.9922 ,25.0255 ,57.4652 ,189.8569 ,60.5322 ,98.2492 ,256.1724 ,163.6926 ,115.9206 ,170.5576 ,8.5084 ,139.1606 ,151.5307 ,67.6941 ,39.1542 ,323.9347 ,183.6418 ,75.2728 ,218.0335 ,294.1343 ,
      		7.4945 ,6.4312 ,52.7262 ,258.7808 ,57.6819 ,253.6580 ,244.1433 ,196.0928 ,79.4159 ,351.2140 ,287.2119 ,185.9758 ,80.3505 ,233.4623 ,142.1633 ,207.3045 ,115.6485 ,227.1412 ,21.1626 ,107.4981 ,348.4452 ,315.1923 ,110.2992 ,309.0652 ,111.7309 ,338.1438 ,267.7832 ,149.8220 ,90.8489 ,3.0529 ,316.3384 ,13.6500 ,294.9891 ,346.3924 ,205.3010 ,61.7462 ,312.4012 ,350.5591 ,253.4483 ,183.1945 ,136.0688 ,124.8951 ,74.0742 ,242.6951 ,155.8620 ,69.8827 ,37.5927 ,239.7447 ,106.5862 ,179.9280 ,
      		117.1244 ,313.7837 ,323.8842 ,6.5135 ,72.3071 ,117.9867 ,355.3379 ,281.7721 ,122.0744 ,76.6907 ,242.8038 ,301.5724 ,335.5875 ,123.7859 ,317.6616 ,247.3597 ,174.4195 ,354.7830 ,84.4706 ,261.1675 ,30.4849 ,61.0899 ,327.9556 ,76.6686 ,273.2818 ,216.0752 ,302.8076 ,132.5189 ,122.5027 ,104.8375 ,312.2711 ,217.4337 ,343.5507 ,319.4154 ,48.7246 ,198.4214 ,37.5390 ,14.0896 ,26.3496 ,311.8206 ,283.7219 ,298.2621 ,122.7231 ,221.4670 ,281.4853 ,136.0943 ,205.4813 ,80.5371 ,29.4276 ,96.0205 ,
      		320.6765 ,203.2009 ,333.0242 ,164.7969 ,99.7858 ,283.3253 ,297.9965 ,4.4574 ,241.3482 ,33.0059 ,41.4369 ,318.6216 ,14.4085 ,86.2680 ,355.7371 ,151.5649 ,41.6009 ,60.2580 ,86.9113 ,267.8423 ,37.0203 ,327.8752 ,136.1798 ,349.2951 ,327.3202 ,105.8485 ,91.2276 ,171.7236 ,36.0465 ,234.7381 ,14.2633 ,3.7822 ,353.7301 ,106.3979 ,214.7654 ,161.9440 ,112.7811 ,22.6673 ,328.8211 ,349.1328 ,349.1267 ,40.0904 ,77.4696 ,222.4105 ,352.7830 ,195.4488 ,247.7483 ,238.2604 ,93.2710 ,194.9768 ,
      		110.6356 ,88.6972 ,29.2928 ,101.0832 ,354.0156 ,161.2448 ,234.7238 ,231.6478 ,338.6644 ,140.5723 ,110.4423 ,117.8069 ,114.0247 ,304.9685 ,321.6601 ,109.0114 ,120.3600 ,195.9211 ,208.4348 ,214.5465 ,88.2353 ,7.3347 ,87.7533 ,26.0379 ,198.4337 ,25.5299 ,27.0467 ,228.7376 ,104.6958 ,285.1865 ,177.5740 ,310.5536 ,55.5047 ,180.5147 ,286.1941 ,27.7585 ,341.7221 ,62.3672 ,279.4352 ,354.5625 ,295.7581 ,115.1222 ,38.4760 ,185.1690 ,330.9685 ,105.6562 ,321.7532 ,51.0050 ,327.7734 ,11.4336 ,
      		113.7847 ,325.1118 ,289.3883 ,326.5754 ,302.6587 ,268.6266 ,248.2543 ,64.1358 ,155.7497 ,56.8429 ,257.3368 ,240.4003 ,90.9311 ,23.1891 ,346.8189 ,290.9709 ,197.7372 ,194.8960 ,306.4654 ,163.1915 ,142.4558 ,121.9209 ,92.8689 ,8.7871 ,232.7180 ,150.0062 ,205.4173 ,22.4358 ,127.7796 ,49.7823 ,45.0464 ,93.2807 ,298.4164 ,143.2070 ,144.3896 ,220.4802 ,84.0707 ,2.6918 ,190.3326 ,180.3239 ,233.5823 ,157.7941 ,247.1447 ,263.3119 ,85.8149 ,178.2260 ,172.3777 ,81.0224 ,148.4086 ,201.7467 ,
      		326.4982 ,330.3744 ,99.0811 ,232.7095 ,17.3510 ,25.7585 ,184.2090 ,315.8727 ,57.4084 ,275.7700 ,317.8834 ,112.2487 ,249.3205 ,305.6368 ,133.7812 ,252.4618 ,265.1105 ,214.0480 ,308.2598 ,322.7776 ,345.6284 ,205.6438 ,63.4593 ,90.2143 ,78.3427 ,205.0262 ,272.7900 ,18.7680 ,245.3891 ,258.1752 ,125.2733 ,185.4201 ,59.3273 ,262.7626 ,14.6551 ,353.2396 ,290.8597 ,226.2415 ,96.3094 ,328.6306 ,345.3980 ,50.0854 ,279.2726 ,303.0951 ,237.4982 ,252.1468 ,160.2211 ,332.7508 ,349.6347 ,137.6472 ,
      		288.9762 ,155.8518 ,59.3115 ,117.1682 ,45.4788 ,327.1985 ,345.3927 ,42.9072 ,216.2445 ,146.9607 ,42.5124 ,106.3712 ,89.3579 ,269.8477 ,1.4432 ,68.3419 ,157.9583 ,7.5725 ,225.9096 ,218.0259 ,300.7196 ,74.3781 ,102.5214 ,195.2422 ,98.3613 ,210.8657 ,90.3176 ,246.0698 ,284.7927 ,291.1157 ,350.5018 ,196.3357 ,176.6913 ,308.0512 ,276.8643 ,205.3961 ,137.9723 ,102.2571 ,38.9301 ,290.7177 ,42.5058 ,269.0155 ,196.3034 ,347.3803 ,273.9836 ,350.4671 ,49.1738 ,180.1337 ,206.1282 ,112.0505 ,
      		181.0917 ,128.4548 ,190.2218 ,0.3041 ,159.2332 ,161.8388 ,109.7277 ,143.7850 ,281.9114 ,246.0286 ,177.2277 ,233.1606 ,135.9210 ,73.4091 ,1.3952 ,99.9437 ,215.3391 ,317.3987 ,298.5916 ,183.9457 ,355.3265 ,166.1692 ,300.4537 ,147.2275 ,268.0670 ,355.5330 ,109.9212 ,61.3126 ,223.2121 ,191.1442 ,129.3919 ,1.2669 ,140.0986 ,153.3130 ,145.8907 ,310.0483 ,210.3941 ,264.1791 ,323.2473 ,269.5584 ,177.3727 ,268.4766 ,230.5279 ,233.5484 ,226.6831 ,146.5196 ,226.5343 ,228.1437 ,337.3625 ,281.6905 ,
      		304.6565 ,276.2999 ,293.5173 ,217.9665 ,125.8020 ,95.2500 ,254.8872 ,314.6191 ,195.9288 ,54.7452 ,299.8711 ,174.4355 ,168.1569 ,16.3397 ,183.7011 ,268.1092 ,152.1352 ,127.8638 ,236.4637 ,7.1069 ,182.5789 ,340.6058 ,248.5611 ,144.6925 ,248.0070 ,217.7978 ,75.2002 ,74.7750 ,318.9691 ,96.8649 ,26.9585 ,299.0439 ,188.3512 ,132.5549 ,184.1468 ,265.2212 ,60.6793 ,235.1041 ,256.8373 ,293.4012 ,97.1138 ,219.4799 ,83.5610 ,201.9761 ,62.0507 ,284.3163 ,312.0184 ,118.6717 ,80.0347 ,346.9638 ,
      		254.4085 ,303.7653 ,10.9924 ,323.7816 ,224.0827 ,113.9505 ,155.4356 ,274.1735 ,282.7483 ,68.3643 ,225.3191 ,59.6266 ,350.2979 ,159.6876 ,328.7322 ,262.1692 ,218.2536 ,94.3143 ,189.5732 ,49.9031 ,49.7153 ,257.6699 ,129.9923 ,270.4955 ,86.5777 ,258.5369 ,258.6517 ,109.9785 ,38.2988 ,142.9228 ,177.2501 ,35.9907 ,67.2341 ,19.9235 ,215.1049 ,319.9954 ,77.9608 ,12.4968 ,253.4125 ,293.3678 ,347.0838 ,220.7444 ,123.2795 ,301.6327 ,42.5042 ,249.3493 ,34.2831 ,143.8941 ,178.2082 ,136.0419 ,
      		60.6951 ,83.4182 ,295.2540 ,166.5273 ,208.7758 ,76.2865 ,257.3766 ,118.8422 ,213.7027 ,327.4153 ,357.9816 ,16.6385 ,287.0794 ,308.7316 ,115.0468 ,137.9331 ,208.8914 ,330.7825 ,143.9743 ,316.8109 ,273.0818 ,54.8183 ,328.9248 ,5.4652 ,52.2642 ,239.3320 ,20.5631 ,136.6164 ,46.7924 ,166.6401 ,302.3929 ,326.1904 ,12.7691 ,21.9066 ,302.6247 ,15.4133 ,98.4925 ,42.2772 ,32.7736 ,9.9442 ,229.5047 ,268.0611 ,247.2377 ,304.4242 ,238.6858 ,140.2927 ,227.1827 ,349.0541 ,230.9772 ,87.5130 ,
      		21.6663 ,336.6598 ,212.5784 ,125.8613 ,217.9270 ,201.6927 ,187.9818 ,21.8897 ,127.1619 ,148.5540 ,71.7726 ,316.8379 ,152.6831 ,238.4588 ,256.8767 ,267.5819 ,259.6015 ,270.7951 ,90.5690 ,351.5053 ,54.3635 ,330.7131 ,307.6448 ,306.7791 ,19.0121 ,32.8385 ,292.7001 ,168.9001 ,133.2911 ,354.4875 ,14.4425 ,191.3274 ,159.6059 ,46.1531 ,142.2678 ,254.7531 ,317.6336 ,8.8631 ,188.8234 ,32.5356 ,288.1416 ,30.8827 ,12.3096 ,138.3250 ,263.7382 ,112.7544 ,46.8018 ,286.0460 ,290.4910 ,308.1095 ,
      		109.3480 ,152.9389 ,88.3404 ,200.5839 ,118.8386 ,121.9188 ,282.1037 ,344.2666 ,210.2905 ,37.6877 ,234.9270 ,161.5002 ,355.6910 ,258.9773 ,300.5230 ,252.4631 ,192.8228 ,322.8546 ,299.3821 ,104.8773 ,56.5315 ,133.3267 ,187.5880 ,35.0568 ,124.3365 ,206.9660 ,15.6869 ,293.3815 ,234.4021 ,112.9141 ,107.3956 ,126.9418 ,117.1039 ,269.4650 ,180.3805 ,189.4062 ,53.5523 ,329.1905 ,117.2063 ,117.9232 ,24.7846 ,352.5882 ,172.6912 ,328.6385 ,333.9422 ,349.1108 ,293.6265 ,333.1596 ,332.0242 ,288.4924 ,
      		48.4492 ,188.5362 ,207.2174 ,357.2991 ,282.2215 ,253.0498 ,268.7937 ,130.1680 ,339.2329 ,231.6603 ,144.9269 ,167.2458 ,352.7118 ,191.5662 ,60.4071 ,53.4078 ,247.4072 ,202.5992 ,326.4503 ,66.4561 ,147.9992 ,262.0657 ,18.0378 ,35.7201 ,196.4548 ,95.6625 ,38.4975 ,94.2111 ,227.5708 ,189.4959 ,28.2588 ,26.2121 ,306.2257 ,231.5660 ,62.4122 ,310.2603 ,7.8658 ,132.5177 ,305.1467 ,255.7002 ,102.1509 ,320.8613 ,215.3081 ,311.5776 ,321.4056 ,153.1599 ,243.2161 ,196.0115 ,340.1047 ,287.3379 ,
      		261.2947 ,293.0517 ,359.3376 ,92.3620 ,72.4909 ,268.8418 ,277.3197 ,185.1422 ,175.3473 ,145.3475 ,317.7709 ,286.6435 ,210.4551 ,14.4429 ,306.4110 ,165.0433 ,68.3138 ,107.7675 ,248.8804 ,1.9825 ,43.2161 ,108.9553 ,319.3889 ,268.8698 ,349.4850 ,195.4903 ,205.9086 ,198.4957 ,189.2258 ,195.1346 ,294.6843 ,343.2127 ,146.9883 ,226.7875 ,110.7934 ,108.6877 ,182.2742 ,211.0564 ,197.9980 ,351.5687 ,58.6696 ,229.1992 ,358.0312 ,265.0087 ,203.7271 ,132.6107 ,144.7700 ,337.1483 ,322.3190 ,241.0835 ,
      		323.5492 ,333.0589 ,304.6837 ,138.0298 ,167.1713 ,286.5267 ,134.1479 ,269.7710 ,173.3113 ,121.1549 ,164.2134 ,41.9434 ,127.6188 ,149.4700 ,6.5389 ,61.9466 ,93.6839 ,308.8383 ,212.2478 ,103.3722 ,359.1816 ,92.8514 ,184.9638 ,266.2271 ,248.8754 ,156.0610 ,279.7192 ,174.8859 ,257.5674 ,176.8956 ,349.7381 ,257.8248 ,32.8958 ,46.6092 ,347.9453 ,82.5222 ,9.4090 ,91.1605 ,172.7233 ,342.7807 ,143.6868 ,260.4620 ,300.3705 ,32.0983 ,220.2811 ,358.4824 ,197.8545 ,192.4150 ,124.8129 ,340.5979 ,
      		349.0557 ,37.1411 ,199.0202 ,151.0665 ,241.7926 ,42.7128 ,95.5203 ,100.3512 ,172.6967 ,285.5818 ,308.8251 ,283.1125 ,243.6505 ,31.3894 ,140.2981 ,240.7326 ,105.9292 ,182.8146 ,325.8282 ,41.8165 ,307.3956 ,38.0987 ,139.0912 ,325.9402 ,72.4320 ,187.4673 ,149.9775 ,319.6610 ,357.1433 ,103.8933 ,177.2916 ,322.2019 ,196.1264 ,77.2650 ,273.4784 ,121.3521 ,174.9508 ,3.0823 ,356.0281 ,236.6217 ,333.2926 ,348.7267 ,96.3121 ,194.5930 ,158.4904 ,273.5479 ,303.2588 ,82.2817 ,98.8433 ,254.2542 ,
      		148.1915 ,46.8726 ,70.3118 ,201.9058 ,215.4580 ,345.6258 ,191.8008 ,219.2331 ,53.5877 ,148.9687 ,100.7249 ,250.3522 ,96.1406 ,77.1841 ,132.3664 ,169.3977 ,121.8222 ,218.0636 ,65.2333 ,316.7677 ,249.9017 ,192.5148 ,20.9384 ,117.3624 ,248.4387 ,232.2231 ,292.3035 ,320.9431 ,113.5319 ,177.7430 ,118.8150 ,46.0520 ,50.4422 ,92.3290 ,31.6904 ,193.9772 ,253.0521 ,202.7061 ,246.5160 ,81.4493 ,71.7856 ,204.3269 ,318.3428 ,152.0152 ,1.5252 ,7.2186 ,109.9097 ,221.5347 ,30.4436 ,80.8237 ,
      		245.0486 ,354.5971 ,122.7862 ,216.4100 ,186.6347 ,8.3249 ,118.7404 ,50.1988 ,90.2958 ,277.1932 ,245.2329 ,14.7683 ,27.8550 ,260.9745 ,37.1555 ,114.1272 ,96.9615 ,17.9159 ,11.2212 ,50.0525 ,143.7578 ,336.1341 ,229.8161 ,87.1420 ,244.6719 ,98.5079 ,185.4857 ,115.8580 ,341.5215 ,126.8505 ,289.2826 ,230.8295 ,303.5972 ,218.2177 ,313.3386 ,145.8587 ,244.4410 ,223.4294 ,189.9841 ,203.1984 ,192.8743 ,141.7575 ,323.3950 ,227.7826 ,197.6843 ,19.4181 ,183.0701 ,63.0528 ,77.4084 ,156.4604 ,
      		196.5445 ,90.1484 ,97.5364 ,190.8527 ,170.3643 ,145.1835 ,37.3513 ,134.4520 ,235.5917 ,195.9116 ,196.1110 ,303.7745 ,260.3387 ,246.4521 ,10.9489 ,110.9261 ,245.6684 ,56.0782 ,328.8503 ,51.0936 ,316.4837 ,77.8566 ,302.9723 ,305.3627 ,120.7673 ,319.8933 ,57.5164 ,305.6794 ,137.4244 ,158.2983 ,42.4295 ,216.3619 ,97.1121 ,240.0765 ,287.7797 ,217.3262 ,2.9465 ,342.8407 ,331.0852 ,231.4567 ,136.6223 ,202.2890 ,317.8123 ,165.4304 ,280.5186 ,215.4812 ,152.0205 ,336.0696 ,147.0351 ,218.0805 ,
      		19.1787 ,169.4750 ,13.4691 ,253.4878 ,0.2125 ,15.1436 ,40.0052 ,50.2470 ,182.9082 ,128.2638 ,97.5252 ,354.1045 ,327.2400 ,235.7504 ,288.7513 ,295.0950 ,88.2624 ,290.9830 ,86.3322 ,202.4484 ,128.7781 ,57.1173 ,279.6676 ,329.8830 ,112.9315 ,316.7145 ,124.6522 ,236.7199 ,358.4843 ,277.9455 ,20.0402 ,156.5542 ,135.4692 ,105.8154 ,293.8088 ,158.7673 ,251.7265 ,228.5752 ,186.8385 ,20.1712 ,242.2927 ,320.8979 ,61.9918 ,231.3880 ,175.4782 ,122.7544 ,255.7536 ,351.0716 ,7.7993 ,323.0301 ,
      		137.9659 ,300.1854 ,62.8961 ,257.9730 ,35.8907 ,120.8197 ,349.1671 ,236.3816 ,282.4286 ,166.0700 ,169.6201 ,177.3451 ,278.3359 ,260.3699 ,69.7565 ,158.6176 ,195.1286 ,205.7143 ,333.6375 ,302.3090 ,53.9572 ,135.4035 ,39.2301 ,9.4406 ,26.8509 ,65.8676 ,275.7878 ,240.1997 ,287.2336 ,103.8612 ,55.9840 ,349.9561 ,297.3690 ,340.8415 ,6.7633 ,142.7571 ,228.1674 ,264.9868 ,328.5542 ,193.5834 ,140.6853 ,1.9166 ,289.3908 ,353.5769 ,326.6087 ,238.4167 ,123.2912 ,86.0941 ,279.0071 ,336.7546 ,
      		345.7174 ,63.2187 ,210.7270 ,184.7226 ,153.8731 ,285.9842 ,336.8817 ,260.8649 ,252.1101 ,248.6212 ,235.2804 ,193.2314 ,89.2497 ,280.6117 ,42.8736 ,231.7997 ,139.3154 ,201.5865 ,230.9171 ,172.4125 ,352.1139 ,86.1095 ,4.3806 ,343.8929 ,112.3228 ,100.1061 ,149.6013 ,214.1880 ,355.0012 ,254.7089 ,114.5953 ,192.4878 ,161.5268 ,180.5714 ,150.3390 ,60.3424 ,142.3743 ,140.0721 ,72.2590 ,294.0907 ,129.5967 ,54.5351 ,204.0748 ,304.1436 ,281.0020 ,223.9345 ,263.1737 ,121.0012 ,51.3761 ,91.8035 ,
      		125.7673 ,100.4882 ,168.3941 ,53.6516 ,46.8942 ,90.9806 ,70.7413 ,288.6122 ,193.5205 ,71.4280 ,154.5182 ,313.8896 ,207.9404 ,199.4091 ,140.8745 ,70.5015 ,225.1458 ,27.7738 ,283.0284 ,20.7089 ,268.6850 ,137.7465 ,245.6681 ,212.7619 ,46.5032 ,193.8608 ,26.7003 ,86.8386 ,137.4008 ,102.8416 ,238.2334 ,355.2605 ,128.4701 ,301.8950 ,81.0358 ,255.3591 ,125.1793 ,192.7308 ,31.8900 ,297.8472 ,75.1806 ,166.8430 ,104.5065 ,291.6731 ,213.3341 ,221.4666 ,271.7095 ,91.7628 ,20.9693 ,298.2799 ,
      		113.6179 ,292.4176 ,344.3902 ,226.5088 ,37.1851 ,307.4354 ,228.0341 ,88.5237 ,74.8339 ,182.7797 ,43.7637 ,326.1672 ,254.8304 ,294.9416 ,138.1754 ,332.3489 ,48.2237 ,257.8500 ,91.6574 ,1.3074 ,43.5209 ,72.5559 ,274.8043 ,136.0980 ,173.5310 ,220.8895 ,96.3577 ,229.8361 ,241.7659 ,331.6929 ,181.0321 ,307.9030 ,348.3906 ,276.8023 ,151.6291 ,97.9127 ,35.1835 ,299.1697 ,46.6560 ,201.4246 ,163.4151 ,16.1447 ,77.1616 ,296.2428 ,193.9175 ,332.7821 ,326.8706 ,33.8499 ,244.1221 ,15.3569 ,
      		152.1600 ,159.0390 ,344.4742 ,214.3143 ,68.4002 ,183.5090 ,187.8584 ,70.9469 ,129.5033 ,315.8981 ,353.3295 ,279.6719 ,23.2205 ,326.1156 ,165.0454 ,300.2602 ,63.6408 ,53.1665 ,326.3984 ,102.7884 ,15.5000 ,180.3774 ,356.6046 ,300.7793 ,142.6679 ,357.5064 ,286.8013 ,303.1437 ,232.5985 ,141.9773 ,326.0555 ,169.4265 ,336.4712 ,198.7888 ,327.5487 ,171.7763 ,153.6555 ,211.9256 ,114.2318 ,53.7831 ,212.1597 ,306.3467 ,99.9994 ,311.4077 ,283.3664 ,279.2433 ,149.4469 ,359.5523 ,284.7162 ,207.2336 ,
      		40.8636 ,206.5736 ,5.1772 ,324.7951 ,121.2110 ,132.6042 ,198.3179 ,229.4870 ,209.7817 ,174.5731 ,228.3679 ,304.9712 ,160.6354 ,180.0286 ,291.7249 ,1.2262 ,57.8558 ,117.0108 ,77.0175 ,322.5636 ,53.3578 ,38.8392 ,114.1923 ,183.1107 ,295.7331 ,358.4344 ,306.6731 ,219.1815 ,13.5367 ,22.8472 ,227.0650 ,295.1576 ,95.5845 ,348.9188 ,198.1394 ,206.5576 ,222.7039 ,26.9691 ,61.3397 ,337.0292 ,96.2263 ,29.9855 ,101.6744 ,261.4126 ,94.6111 ,75.8094 ,99.7666 ,172.9518 ,265.5177 ,108.4763};
#endif

#ifdef INPUT_ARRAY_SIZE_1750
#ifdef INPUT_DATA_IN_CCM
   __attribute__((section(".ccmramdata")))
#endif
      float arr_input[1750] = {48.3711 ,305.0761 ,274.9589 ,91.8248 ,178.3566 ,161.8168 ,234.5735 ,283.9404 ,33.7895 ,10.2051 ,300.8754 ,155.7961 ,274.4208 ,0.7582 ,160.3394 ,259.7544 ,82.3544 ,340.2975 ,324.5139 ,11.0124 ,9.1605 ,194.9085 ,338.0937 ,137.2335 ,77.9758 ,151.9620 ,10.4547 ,79.8090 ,157.6395 ,178.4924 ,83.9104 ,83.1120 ,78.7612 ,165.4572 ,104.3214 ,7.7363 ,301.5281 ,200.3236 ,231.2260 ,66.9263 ,357.3156 ,309.5808 ,43.5204 ,119.7703 ,259.7344 ,256.0290 ,337.1186 ,151.9585 ,298.8128 ,241.3100 ,
   	   109.2127 ,211.5290 ,317.6924 ,304.6311 ,181.9022 ,212.0408 ,12.4293 ,87.3864 ,287.0655 ,149.1530 ,62.2827 ,197.5676 ,253.0947 ,242.8149 ,134.8931 ,158.0262 ,183.0335 ,280.2393 ,187.5378 ,141.5718 ,176.2897 ,10.6470 ,15.6554 ,253.2176 ,353.9476 ,213.5461 ,141.6959 ,61.3257 ,180.8059 ,353.5476 ,277.3883 ,194.2623 ,309.7043 ,83.5834 ,184.9578 ,342.8883 ,208.0061 ,165.2874 ,96.9406 ,197.2787 ,344.5619 ,2.0553 ,282.1159 ,295.3749 ,319.0246 ,266.5812 ,291.2904 ,186.7242 ,202.0888 ,153.3926 ,
   	   20.2044 ,313.2037 ,205.1998 ,71.9422 ,181.6994 ,174.5730 ,128.4444 ,124.5881 ,193.8524 ,224.4562 ,220.4829 ,164.9328 ,10.0710 ,82.6578 ,63.7961 ,210.4059 ,309.9632 ,287.4380 ,286.9551 ,293.9175 ,91.9059 ,303.0281 ,242.3209 ,29.9643 ,6.0086 ,5.2416 ,272.0112 ,89.8413 ,39.4159 ,224.9288 ,123.9922 ,25.0255 ,57.4652 ,189.8569 ,60.5322 ,98.2492 ,256.1724 ,163.6926 ,115.9206 ,170.5576 ,8.5084 ,139.1606 ,151.5307 ,67.6941 ,39.1542 ,323.9347 ,183.6418 ,75.2728 ,218.0335 ,294.1343 ,
   	   7.4945 ,6.4312 ,52.7262 ,258.7808 ,57.6819 ,253.6580 ,244.1433 ,196.0928 ,79.4159 ,351.2140 ,287.2119 ,185.9758 ,80.3505 ,233.4623 ,142.1633 ,207.3045 ,115.6485 ,227.1412 ,21.1626 ,107.4981 ,348.4452 ,315.1923 ,110.2992 ,309.0652 ,111.7309 ,338.1438 ,267.7832 ,149.8220 ,90.8489 ,3.0529 ,316.3384 ,13.6500 ,294.9891 ,346.3924 ,205.3010 ,61.7462 ,312.4012 ,350.5591 ,253.4483 ,183.1945 ,136.0688 ,124.8951 ,74.0742 ,242.6951 ,155.8620 ,69.8827 ,37.5927 ,239.7447 ,106.5862 ,179.9280 ,
   	   117.1244 ,313.7837 ,323.8842 ,6.5135 ,72.3071 ,117.9867 ,355.3379 ,281.7721 ,122.0744 ,76.6907 ,242.8038 ,301.5724 ,335.5875 ,123.7859 ,317.6616 ,247.3597 ,174.4195 ,354.7830 ,84.4706 ,261.1675 ,30.4849 ,61.0899 ,327.9556 ,76.6686 ,273.2818 ,216.0752 ,302.8076 ,132.5189 ,122.5027 ,104.8375 ,312.2711 ,217.4337 ,343.5507 ,319.4154 ,48.7246 ,198.4214 ,37.5390 ,14.0896 ,26.3496 ,311.8206 ,283.7219 ,298.2621 ,122.7231 ,221.4670 ,281.4853 ,136.0943 ,205.4813 ,80.5371 ,29.4276 ,96.0205 ,
   	   320.6765 ,203.2009 ,333.0242 ,164.7969 ,99.7858 ,283.3253 ,297.9965 ,4.4574 ,241.3482 ,33.0059 ,41.4369 ,318.6216 ,14.4085 ,86.2680 ,355.7371 ,151.5649 ,41.6009 ,60.2580 ,86.9113 ,267.8423 ,37.0203 ,327.8752 ,136.1798 ,349.2951 ,327.3202 ,105.8485 ,91.2276 ,171.7236 ,36.0465 ,234.7381 ,14.2633 ,3.7822 ,353.7301 ,106.3979 ,214.7654 ,161.9440 ,112.7811 ,22.6673 ,328.8211 ,349.1328 ,349.1267 ,40.0904 ,77.4696 ,222.4105 ,352.7830 ,195.4488 ,247.7483 ,238.2604 ,93.2710 ,194.9768 ,
   	   110.6356 ,88.6972 ,29.2928 ,101.0832 ,354.0156 ,161.2448 ,234.7238 ,231.6478 ,338.6644 ,140.5723 ,110.4423 ,117.8069 ,114.0247 ,304.9685 ,321.6601 ,109.0114 ,120.3600 ,195.9211 ,208.4348 ,214.5465 ,88.2353 ,7.3347 ,87.7533 ,26.0379 ,198.4337 ,25.5299 ,27.0467 ,228.7376 ,104.6958 ,285.1865 ,177.5740 ,310.5536 ,55.5047 ,180.5147 ,286.1941 ,27.7585 ,341.7221 ,62.3672 ,279.4352 ,354.5625 ,295.7581 ,115.1222 ,38.4760 ,185.1690 ,330.9685 ,105.6562 ,321.7532 ,51.0050 ,327.7734 ,11.4336 ,
   	   113.7847 ,325.1118 ,289.3883 ,326.5754 ,302.6587 ,268.6266 ,248.2543 ,64.1358 ,155.7497 ,56.8429 ,257.3368 ,240.4003 ,90.9311 ,23.1891 ,346.8189 ,290.9709 ,197.7372 ,194.8960 ,306.4654 ,163.1915 ,142.4558 ,121.9209 ,92.8689 ,8.7871 ,232.7180 ,150.0062 ,205.4173 ,22.4358 ,127.7796 ,49.7823 ,45.0464 ,93.2807 ,298.4164 ,143.2070 ,144.3896 ,220.4802 ,84.0707 ,2.6918 ,190.3326 ,180.3239 ,233.5823 ,157.7941 ,247.1447 ,263.3119 ,85.8149 ,178.2260 ,172.3777 ,81.0224 ,148.4086 ,201.7467 ,
   	   326.4982 ,330.3744 ,99.0811 ,232.7095 ,17.3510 ,25.7585 ,184.2090 ,315.8727 ,57.4084 ,275.7700 ,317.8834 ,112.2487 ,249.3205 ,305.6368 ,133.7812 ,252.4618 ,265.1105 ,214.0480 ,308.2598 ,322.7776 ,345.6284 ,205.6438 ,63.4593 ,90.2143 ,78.3427 ,205.0262 ,272.7900 ,18.7680 ,245.3891 ,258.1752 ,125.2733 ,185.4201 ,59.3273 ,262.7626 ,14.6551 ,353.2396 ,290.8597 ,226.2415 ,96.3094 ,328.6306 ,345.3980 ,50.0854 ,279.2726 ,303.0951 ,237.4982 ,252.1468 ,160.2211 ,332.7508 ,349.6347 ,137.6472 ,
   	   288.9762 ,155.8518 ,59.3115 ,117.1682 ,45.4788 ,327.1985 ,345.3927 ,42.9072 ,216.2445 ,146.9607 ,42.5124 ,106.3712 ,89.3579 ,269.8477 ,1.4432 ,68.3419 ,157.9583 ,7.5725 ,225.9096 ,218.0259 ,300.7196 ,74.3781 ,102.5214 ,195.2422 ,98.3613 ,210.8657 ,90.3176 ,246.0698 ,284.7927 ,291.1157 ,350.5018 ,196.3357 ,176.6913 ,308.0512 ,276.8643 ,205.3961 ,137.9723 ,102.2571 ,38.9301 ,290.7177 ,42.5058 ,269.0155 ,196.3034 ,347.3803 ,273.9836 ,350.4671 ,49.1738 ,180.1337 ,206.1282 ,112.0505 ,
   	   181.0917 ,128.4548 ,190.2218 ,0.3041 ,159.2332 ,161.8388 ,109.7277 ,143.7850 ,281.9114 ,246.0286 ,177.2277 ,233.1606 ,135.9210 ,73.4091 ,1.3952 ,99.9437 ,215.3391 ,317.3987 ,298.5916 ,183.9457 ,355.3265 ,166.1692 ,300.4537 ,147.2275 ,268.0670 ,355.5330 ,109.9212 ,61.3126 ,223.2121 ,191.1442 ,129.3919 ,1.2669 ,140.0986 ,153.3130 ,145.8907 ,310.0483 ,210.3941 ,264.1791 ,323.2473 ,269.5584 ,177.3727 ,268.4766 ,230.5279 ,233.5484 ,226.6831 ,146.5196 ,226.5343 ,228.1437 ,337.3625 ,281.6905 ,
   	   304.6565 ,276.2999 ,293.5173 ,217.9665 ,125.8020 ,95.2500 ,254.8872 ,314.6191 ,195.9288 ,54.7452 ,299.8711 ,174.4355 ,168.1569 ,16.3397 ,183.7011 ,268.1092 ,152.1352 ,127.8638 ,236.4637 ,7.1069 ,182.5789 ,340.6058 ,248.5611 ,144.6925 ,248.0070 ,217.7978 ,75.2002 ,74.7750 ,318.9691 ,96.8649 ,26.9585 ,299.0439 ,188.3512 ,132.5549 ,184.1468 ,265.2212 ,60.6793 ,235.1041 ,256.8373 ,293.4012 ,97.1138 ,219.4799 ,83.5610 ,201.9761 ,62.0507 ,284.3163 ,312.0184 ,118.6717 ,80.0347 ,346.9638 ,
   	   254.4085 ,303.7653 ,10.9924 ,323.7816 ,224.0827 ,113.9505 ,155.4356 ,274.1735 ,282.7483 ,68.3643 ,225.3191 ,59.6266 ,350.2979 ,159.6876 ,328.7322 ,262.1692 ,218.2536 ,94.3143 ,189.5732 ,49.9031 ,49.7153 ,257.6699 ,129.9923 ,270.4955 ,86.5777 ,258.5369 ,258.6517 ,109.9785 ,38.2988 ,142.9228 ,177.2501 ,35.9907 ,67.2341 ,19.9235 ,215.1049 ,319.9954 ,77.9608 ,12.4968 ,253.4125 ,293.3678 ,347.0838 ,220.7444 ,123.2795 ,301.6327 ,42.5042 ,249.3493 ,34.2831 ,143.8941 ,178.2082 ,136.0419 ,
   	   60.6951 ,83.4182 ,295.2540 ,166.5273 ,208.7758 ,76.2865 ,257.3766 ,118.8422 ,213.7027 ,327.4153 ,357.9816 ,16.6385 ,287.0794 ,308.7316 ,115.0468 ,137.9331 ,208.8914 ,330.7825 ,143.9743 ,316.8109 ,273.0818 ,54.8183 ,328.9248 ,5.4652 ,52.2642 ,239.3320 ,20.5631 ,136.6164 ,46.7924 ,166.6401 ,302.3929 ,326.1904 ,12.7691 ,21.9066 ,302.6247 ,15.4133 ,98.4925 ,42.2772 ,32.7736 ,9.9442 ,229.5047 ,268.0611 ,247.2377 ,304.4242 ,238.6858 ,140.2927 ,227.1827 ,349.0541 ,230.9772 ,87.5130 ,
   	   21.6663 ,336.6598 ,212.5784 ,125.8613 ,217.9270 ,201.6927 ,187.9818 ,21.8897 ,127.1619 ,148.5540 ,71.7726 ,316.8379 ,152.6831 ,238.4588 ,256.8767 ,267.5819 ,259.6015 ,270.7951 ,90.5690 ,351.5053 ,54.3635 ,330.7131 ,307.6448 ,306.7791 ,19.0121 ,32.8385 ,292.7001 ,168.9001 ,133.2911 ,354.4875 ,14.4425 ,191.3274 ,159.6059 ,46.1531 ,142.2678 ,254.7531 ,317.6336 ,8.8631 ,188.8234 ,32.5356 ,288.1416 ,30.8827 ,12.3096 ,138.3250 ,263.7382 ,112.7544 ,46.8018 ,286.0460 ,290.4910 ,308.1095 ,
   	   109.3480 ,152.9389 ,88.3404 ,200.5839 ,118.8386 ,121.9188 ,282.1037 ,344.2666 ,210.2905 ,37.6877 ,234.9270 ,161.5002 ,355.6910 ,258.9773 ,300.5230 ,252.4631 ,192.8228 ,322.8546 ,299.3821 ,104.8773 ,56.5315 ,133.3267 ,187.5880 ,35.0568 ,124.3365 ,206.9660 ,15.6869 ,293.3815 ,234.4021 ,112.9141 ,107.3956 ,126.9418 ,117.1039 ,269.4650 ,180.3805 ,189.4062 ,53.5523 ,329.1905 ,117.2063 ,117.9232 ,24.7846 ,352.5882 ,172.6912 ,328.6385 ,333.9422 ,349.1108 ,293.6265 ,333.1596 ,332.0242 ,288.4924 ,
   	   48.4492 ,188.5362 ,207.2174 ,357.2991 ,282.2215 ,253.0498 ,268.7937 ,130.1680 ,339.2329 ,231.6603 ,144.9269 ,167.2458 ,352.7118 ,191.5662 ,60.4071 ,53.4078 ,247.4072 ,202.5992 ,326.4503 ,66.4561 ,147.9992 ,262.0657 ,18.0378 ,35.7201 ,196.4548 ,95.6625 ,38.4975 ,94.2111 ,227.5708 ,189.4959 ,28.2588 ,26.2121 ,306.2257 ,231.5660 ,62.4122 ,310.2603 ,7.8658 ,132.5177 ,305.1467 ,255.7002 ,102.1509 ,320.8613 ,215.3081 ,311.5776 ,321.4056 ,153.1599 ,243.2161 ,196.0115 ,340.1047 ,287.3379 ,
   	   261.2947 ,293.0517 ,359.3376 ,92.3620 ,72.4909 ,268.8418 ,277.3197 ,185.1422 ,175.3473 ,145.3475 ,317.7709 ,286.6435 ,210.4551 ,14.4429 ,306.4110 ,165.0433 ,68.3138 ,107.7675 ,248.8804 ,1.9825 ,43.2161 ,108.9553 ,319.3889 ,268.8698 ,349.4850 ,195.4903 ,205.9086 ,198.4957 ,189.2258 ,195.1346 ,294.6843 ,343.2127 ,146.9883 ,226.7875 ,110.7934 ,108.6877 ,182.2742 ,211.0564 ,197.9980 ,351.5687 ,58.6696 ,229.1992 ,358.0312 ,265.0087 ,203.7271 ,132.6107 ,144.7700 ,337.1483 ,322.3190 ,241.0835 ,
   	   323.5492 ,333.0589 ,304.6837 ,138.0298 ,167.1713 ,286.5267 ,134.1479 ,269.7710 ,173.3113 ,121.1549 ,164.2134 ,41.9434 ,127.6188 ,149.4700 ,6.5389 ,61.9466 ,93.6839 ,308.8383 ,212.2478 ,103.3722 ,359.1816 ,92.8514 ,184.9638 ,266.2271 ,248.8754 ,156.0610 ,279.7192 ,174.8859 ,257.5674 ,176.8956 ,349.7381 ,257.8248 ,32.8958 ,46.6092 ,347.9453 ,82.5222 ,9.4090 ,91.1605 ,172.7233 ,342.7807 ,143.6868 ,260.4620 ,300.3705 ,32.0983 ,220.2811 ,358.4824 ,197.8545 ,192.4150 ,124.8129 ,340.5979 ,
   	   349.0557 ,37.1411 ,199.0202 ,151.0665 ,241.7926 ,42.7128 ,95.5203 ,100.3512 ,172.6967 ,285.5818 ,308.8251 ,283.1125 ,243.6505 ,31.3894 ,140.2981 ,240.7326 ,105.9292 ,182.8146 ,325.8282 ,41.8165 ,307.3956 ,38.0987 ,139.0912 ,325.9402 ,72.4320 ,187.4673 ,149.9775 ,319.6610 ,357.1433 ,103.8933 ,177.2916 ,322.2019 ,196.1264 ,77.2650 ,273.4784 ,121.3521 ,174.9508 ,3.0823 ,356.0281 ,236.6217 ,333.2926 ,348.7267 ,96.3121 ,194.5930 ,158.4904 ,273.5479 ,303.2588 ,82.2817 ,98.8433 ,254.2542 ,
   	   148.1915 ,46.8726 ,70.3118 ,201.9058 ,215.4580 ,345.6258 ,191.8008 ,219.2331 ,53.5877 ,148.9687 ,100.7249 ,250.3522 ,96.1406 ,77.1841 ,132.3664 ,169.3977 ,121.8222 ,218.0636 ,65.2333 ,316.7677 ,249.9017 ,192.5148 ,20.9384 ,117.3624 ,248.4387 ,232.2231 ,292.3035 ,320.9431 ,113.5319 ,177.7430 ,118.8150 ,46.0520 ,50.4422 ,92.3290 ,31.6904 ,193.9772 ,253.0521 ,202.7061 ,246.5160 ,81.4493 ,71.7856 ,204.3269 ,318.3428 ,152.0152 ,1.5252 ,7.2186 ,109.9097 ,221.5347 ,30.4436 ,80.8237 ,
   	   245.0486 ,354.5971 ,122.7862 ,216.4100 ,186.6347 ,8.3249 ,118.7404 ,50.1988 ,90.2958 ,277.1932 ,245.2329 ,14.7683 ,27.8550 ,260.9745 ,37.1555 ,114.1272 ,96.9615 ,17.9159 ,11.2212 ,50.0525 ,143.7578 ,336.1341 ,229.8161 ,87.1420 ,244.6719 ,98.5079 ,185.4857 ,115.8580 ,341.5215 ,126.8505 ,289.2826 ,230.8295 ,303.5972 ,218.2177 ,313.3386 ,145.8587 ,244.4410 ,223.4294 ,189.9841 ,203.1984 ,192.8743 ,141.7575 ,323.3950 ,227.7826 ,197.6843 ,19.4181 ,183.0701 ,63.0528 ,77.4084 ,156.4604 ,
   	   196.5445 ,90.1484 ,97.5364 ,190.8527 ,170.3643 ,145.1835 ,37.3513 ,134.4520 ,235.5917 ,195.9116 ,196.1110 ,303.7745 ,260.3387 ,246.4521 ,10.9489 ,110.9261 ,245.6684 ,56.0782 ,328.8503 ,51.0936 ,316.4837 ,77.8566 ,302.9723 ,305.3627 ,120.7673 ,319.8933 ,57.5164 ,305.6794 ,137.4244 ,158.2983 ,42.4295 ,216.3619 ,97.1121 ,240.0765 ,287.7797 ,217.3262 ,2.9465 ,342.8407 ,331.0852 ,231.4567 ,136.6223 ,202.2890 ,317.8123 ,165.4304 ,280.5186 ,215.4812 ,152.0205 ,336.0696 ,147.0351 ,218.0805 ,
   	   19.1787 ,169.4750 ,13.4691 ,253.4878 ,0.2125 ,15.1436 ,40.0052 ,50.2470 ,182.9082 ,128.2638 ,97.5252 ,354.1045 ,327.2400 ,235.7504 ,288.7513 ,295.0950 ,88.2624 ,290.9830 ,86.3322 ,202.4484 ,128.7781 ,57.1173 ,279.6676 ,329.8830 ,112.9315 ,316.7145 ,124.6522 ,236.7199 ,358.4843 ,277.9455 ,20.0402 ,156.5542 ,135.4692 ,105.8154 ,293.8088 ,158.7673 ,251.7265 ,228.5752 ,186.8385 ,20.1712 ,242.2927 ,320.8979 ,61.9918 ,231.3880 ,175.4782 ,122.7544 ,255.7536 ,351.0716 ,7.7993 ,323.0301 ,
   	   137.9659 ,300.1854 ,62.8961 ,257.9730 ,35.8907 ,120.8197 ,349.1671 ,236.3816 ,282.4286 ,166.0700 ,169.6201 ,177.3451 ,278.3359 ,260.3699 ,69.7565 ,158.6176 ,195.1286 ,205.7143 ,333.6375 ,302.3090 ,53.9572 ,135.4035 ,39.2301 ,9.4406 ,26.8509 ,65.8676 ,275.7878 ,240.1997 ,287.2336 ,103.8612 ,55.9840 ,349.9561 ,297.3690 ,340.8415 ,6.7633 ,142.7571 ,228.1674 ,264.9868 ,328.5542 ,193.5834 ,140.6853 ,1.9166 ,289.3908 ,353.5769 ,326.6087 ,238.4167 ,123.2912 ,86.0941 ,279.0071 ,336.7546 ,
   	   345.7174 ,63.2187 ,210.7270 ,184.7226 ,153.8731 ,285.9842 ,336.8817 ,260.8649 ,252.1101 ,248.6212 ,235.2804 ,193.2314 ,89.2497 ,280.6117 ,42.8736 ,231.7997 ,139.3154 ,201.5865 ,230.9171 ,172.4125 ,352.1139 ,86.1095 ,4.3806 ,343.8929 ,112.3228 ,100.1061 ,149.6013 ,214.1880 ,355.0012 ,254.7089 ,114.5953 ,192.4878 ,161.5268 ,180.5714 ,150.3390 ,60.3424 ,142.3743 ,140.0721 ,72.2590 ,294.0907 ,129.5967 ,54.5351 ,204.0748 ,304.1436 ,281.0020 ,223.9345 ,263.1737 ,121.0012 ,51.3761 ,91.8035 ,
   	   125.7673 ,100.4882 ,168.3941 ,53.6516 ,46.8942 ,90.9806 ,70.7413 ,288.6122 ,193.5205 ,71.4280 ,154.5182 ,313.8896 ,207.9404 ,199.4091 ,140.8745 ,70.5015 ,225.1458 ,27.7738 ,283.0284 ,20.7089 ,268.6850 ,137.7465 ,245.6681 ,212.7619 ,46.5032 ,193.8608 ,26.7003 ,86.8386 ,137.4008 ,102.8416 ,238.2334 ,355.2605 ,128.4701 ,301.8950 ,81.0358 ,255.3591 ,125.1793 ,192.7308 ,31.8900 ,297.8472 ,75.1806 ,166.8430 ,104.5065 ,291.6731 ,213.3341 ,221.4666 ,271.7095 ,91.7628 ,20.9693 ,298.2799 ,
   	   113.6179 ,292.4176 ,344.3902 ,226.5088 ,37.1851 ,307.4354 ,228.0341 ,88.5237 ,74.8339 ,182.7797 ,43.7637 ,326.1672 ,254.8304 ,294.9416 ,138.1754 ,332.3489 ,48.2237 ,257.8500 ,91.6574 ,1.3074 ,43.5209 ,72.5559 ,274.8043 ,136.0980 ,173.5310 ,220.8895 ,96.3577 ,229.8361 ,241.7659 ,331.6929 ,181.0321 ,307.9030 ,348.3906 ,276.8023 ,151.6291 ,97.9127 ,35.1835 ,299.1697 ,46.6560 ,201.4246 ,163.4151 ,16.1447 ,77.1616 ,296.2428 ,193.9175 ,332.7821 ,326.8706 ,33.8499 ,244.1221 ,15.3569 ,
   	   152.1600 ,159.0390 ,344.4742 ,214.3143 ,68.4002 ,183.5090 ,187.8584 ,70.9469 ,129.5033 ,315.8981 ,353.3295 ,279.6719 ,23.2205 ,326.1156 ,165.0454 ,300.2602 ,63.6408 ,53.1665 ,326.3984 ,102.7884 ,15.5000 ,180.3774 ,356.6046 ,300.7793 ,142.6679 ,357.5064 ,286.8013 ,303.1437 ,232.5985 ,141.9773 ,326.0555 ,169.4265 ,336.4712 ,198.7888 ,327.5487 ,171.7763 ,153.6555 ,211.9256 ,114.2318 ,53.7831 ,212.1597 ,306.3467 ,99.9994 ,311.4077 ,283.3664 ,279.2433 ,149.4469 ,359.5523 ,284.7162 ,207.2336 ,
   	   40.8636 ,206.5736 ,5.1772 ,324.7951 ,121.2110 ,132.6042 ,198.3179 ,229.4870 ,209.7817 ,174.5731 ,228.3679 ,304.9712 ,160.6354 ,180.0286 ,291.7249 ,1.2262 ,57.8558 ,117.0108 ,77.0175 ,322.5636 ,53.3578 ,38.8392 ,114.1923 ,183.1107 ,295.7331 ,358.4344 ,306.6731 ,219.1815 ,13.5367 ,22.8472 ,227.0650 ,295.1576 ,95.5845 ,348.9188 ,198.1394 ,206.5576 ,222.7039 ,26.9691 ,61.3397 ,337.0292 ,96.2263 ,29.9855 ,101.6744 ,261.4126 ,94.6111 ,75.8094 ,99.7666 ,172.9518 ,265.5177 ,108.4763 ,
   	   314.4635 ,351.3177 ,295.9259 ,27.0452 ,113.5651 ,333.2829 ,309.3784 ,47.9712 ,159.2008 ,131.0193 ,269.0891 ,10.3355 ,113.5717 ,269.9207 ,319.2733 ,14.6255 ,211.8072 ,238.8991 ,314.2501 ,152.8486 ,350.2979 ,71.0733 ,41.3145 ,46.8164 ,211.2206 ,44.0786 ,95.9749 ,70.6686 ,19.9057 ,346.4580 ,120.5731 ,347.0457 ,260.3642 ,79.1169 ,335.7168 ,3.3667 ,353.3957 ,11.6152 ,91.1928 ,198.7046 ,3.3040 ,275.2963 ,30.4755 ,294.1511 ,12.6376 ,190.1368 ,75.3973 ,103.9551 ,176.5744 ,133.6961 ,
   	   141.1128 ,235.2350 ,70.2869 ,65.3404 ,246.3818 ,106.9066 ,335.8639 ,153.4464 ,170.6476 ,8.3413 ,7.4360 ,37.7164 ,225.2261 ,239.2356 ,342.7911 ,155.6890 ,254.7614 ,123.6968 ,26.6623 ,151.2668 ,252.5848 ,289.5206 ,342.7141 ,299.5823 ,202.9012 ,198.1318 ,180.3943 ,171.9383 ,244.9770 ,207.2543 ,308.5783 ,162.0267 ,169.6230 ,299.5485 ,243.2291 ,188.8024 ,202.8407 ,290.0535 ,218.6575 ,93.2941 ,111.6876 ,217.6578 ,16.5053 ,164.7275 ,321.0865 ,83.5718 ,159.8962 ,251.8217 ,333.1814 ,250.6584 ,
   	   225.2989 ,138.2022 ,157.4493 ,231.1009 ,128.2752 ,282.5537 ,2.9486 ,270.5103 ,267.1368 ,110.3184 ,5.3859 ,121.7372 ,212.1069 ,283.3009 ,313.3318 ,75.0827 ,29.4253 ,43.1590 ,356.0574 ,232.3572 ,46.2113 ,248.6755 ,345.4120 ,218.6773 ,83.7260 ,346.4602 ,252.1992 ,65.8743 ,275.8385 ,181.5029 ,206.6555 ,131.6834 ,105.7505 ,151.3572 ,189.5048 ,166.1195 ,311.8556 ,26.7140 ,71.6362 ,337.5019 ,218.8289 ,222.3107 ,226.7100 ,87.6582 ,142.0845 ,75.6534 ,54.7140 ,356.2244 ,267.7731 ,316.4894 ,
   	   0.5268 ,253.6096 ,110.6143 ,179.2479 ,243.0905 ,11.2273 ,133.4734 ,199.4024 ,314.7762 ,184.7545 ,114.3300 ,217.3539 ,210.1003 ,105.2240 ,197.2986 ,99.4042 ,4.0655 ,111.8612 ,31.1151 ,177.0809 ,180.4136 ,313.2799 ,269.2464 ,269.7761 ,356.2720 ,95.2841 ,134.1848 ,83.0006 ,36.8953 ,185.4825 ,184.0782 ,46.7010 ,332.1148 ,352.2612 ,24.5901 ,1.1416 ,22.2470 ,263.4230 ,306.9077 ,23.8200 ,3.2264 ,193.6608 ,119.7761 ,6.7456 ,3.1677 ,76.0894 ,72.0395 ,106.3307 ,198.2397 ,90.4967 ,
   	   84.0660 ,75.8696 ,319.3204 ,85.8929 ,199.9189 ,162.9480 ,119.3058 ,146.4337 ,5.7568 ,66.6172 ,230.4501 ,274.1354 ,78.6131 ,63.5507 ,326.0493 ,35.2009 ,286.1498 ,316.0987 ,52.6676 ,299.8708 ,54.0204 ,15.5185 ,103.0440 ,123.9564 ,212.2345 ,159.3078 ,285.6445 ,239.3161 ,42.9098 ,72.8524 ,268.6187 ,41.7367 ,342.9487 ,292.1616 ,79.1412 ,103.0001 ,90.7650 ,152.2239 ,89.5103 ,11.6147 ,90.6362 ,70.1275 ,125.9727 ,163.5353 ,314.7524 ,237.4401 ,221.5736 ,311.2304 ,139.1520 ,153.3938};

#endif

#ifdef INPUT_ARRAY_SIZE_2000
#ifdef INPUT_DATA_IN_CCM
   __attribute__((section(".ccmramdata")))
#endif
     float arr_input[2000] = {48.3711 ,305.0761 ,274.9589 ,91.8248 ,178.3566 ,161.8168 ,234.5735 ,283.9404 ,33.7895 ,10.2051 ,300.8754 ,155.7961 ,274.4208 ,0.7582 ,160.3394 ,259.7544 ,82.3544 ,340.2975 ,324.5139 ,11.0124 ,9.1605 ,194.9085 ,338.0937 ,137.2335 ,77.9758 ,151.9620 ,10.4547 ,79.8090 ,157.6395 ,178.4924 ,83.9104 ,83.1120 ,78.7612 ,165.4572 ,104.3214 ,7.7363 ,301.5281 ,200.3236 ,231.2260 ,66.9263 ,357.3156 ,309.5808 ,43.5204 ,119.7703 ,259.7344 ,256.0290 ,337.1186 ,151.9585 ,298.8128 ,241.3100 ,
  	   109.2127 ,211.5290 ,317.6924 ,304.6311 ,181.9022 ,212.0408 ,12.4293 ,87.3864 ,287.0655 ,149.1530 ,62.2827 ,197.5676 ,253.0947 ,242.8149 ,134.8931 ,158.0262 ,183.0335 ,280.2393 ,187.5378 ,141.5718 ,176.2897 ,10.6470 ,15.6554 ,253.2176 ,353.9476 ,213.5461 ,141.6959 ,61.3257 ,180.8059 ,353.5476 ,277.3883 ,194.2623 ,309.7043 ,83.5834 ,184.9578 ,342.8883 ,208.0061 ,165.2874 ,96.9406 ,197.2787 ,344.5619 ,2.0553 ,282.1159 ,295.3749 ,319.0246 ,266.5812 ,291.2904 ,186.7242 ,202.0888 ,153.3926 ,
  	   20.2044 ,313.2037 ,205.1998 ,71.9422 ,181.6994 ,174.5730 ,128.4444 ,124.5881 ,193.8524 ,224.4562 ,220.4829 ,164.9328 ,10.0710 ,82.6578 ,63.7961 ,210.4059 ,309.9632 ,287.4380 ,286.9551 ,293.9175 ,91.9059 ,303.0281 ,242.3209 ,29.9643 ,6.0086 ,5.2416 ,272.0112 ,89.8413 ,39.4159 ,224.9288 ,123.9922 ,25.0255 ,57.4652 ,189.8569 ,60.5322 ,98.2492 ,256.1724 ,163.6926 ,115.9206 ,170.5576 ,8.5084 ,139.1606 ,151.5307 ,67.6941 ,39.1542 ,323.9347 ,183.6418 ,75.2728 ,218.0335 ,294.1343 ,
  	   7.4945 ,6.4312 ,52.7262 ,258.7808 ,57.6819 ,253.6580 ,244.1433 ,196.0928 ,79.4159 ,351.2140 ,287.2119 ,185.9758 ,80.3505 ,233.4623 ,142.1633 ,207.3045 ,115.6485 ,227.1412 ,21.1626 ,107.4981 ,348.4452 ,315.1923 ,110.2992 ,309.0652 ,111.7309 ,338.1438 ,267.7832 ,149.8220 ,90.8489 ,3.0529 ,316.3384 ,13.6500 ,294.9891 ,346.3924 ,205.3010 ,61.7462 ,312.4012 ,350.5591 ,253.4483 ,183.1945 ,136.0688 ,124.8951 ,74.0742 ,242.6951 ,155.8620 ,69.8827 ,37.5927 ,239.7447 ,106.5862 ,179.9280 ,
  	   117.1244 ,313.7837 ,323.8842 ,6.5135 ,72.3071 ,117.9867 ,355.3379 ,281.7721 ,122.0744 ,76.6907 ,242.8038 ,301.5724 ,335.5875 ,123.7859 ,317.6616 ,247.3597 ,174.4195 ,354.7830 ,84.4706 ,261.1675 ,30.4849 ,61.0899 ,327.9556 ,76.6686 ,273.2818 ,216.0752 ,302.8076 ,132.5189 ,122.5027 ,104.8375 ,312.2711 ,217.4337 ,343.5507 ,319.4154 ,48.7246 ,198.4214 ,37.5390 ,14.0896 ,26.3496 ,311.8206 ,283.7219 ,298.2621 ,122.7231 ,221.4670 ,281.4853 ,136.0943 ,205.4813 ,80.5371 ,29.4276 ,96.0205 ,
  	   320.6765 ,203.2009 ,333.0242 ,164.7969 ,99.7858 ,283.3253 ,297.9965 ,4.4574 ,241.3482 ,33.0059 ,41.4369 ,318.6216 ,14.4085 ,86.2680 ,355.7371 ,151.5649 ,41.6009 ,60.2580 ,86.9113 ,267.8423 ,37.0203 ,327.8752 ,136.1798 ,349.2951 ,327.3202 ,105.8485 ,91.2276 ,171.7236 ,36.0465 ,234.7381 ,14.2633 ,3.7822 ,353.7301 ,106.3979 ,214.7654 ,161.9440 ,112.7811 ,22.6673 ,328.8211 ,349.1328 ,349.1267 ,40.0904 ,77.4696 ,222.4105 ,352.7830 ,195.4488 ,247.7483 ,238.2604 ,93.2710 ,194.9768 ,
  	   110.6356 ,88.6972 ,29.2928 ,101.0832 ,354.0156 ,161.2448 ,234.7238 ,231.6478 ,338.6644 ,140.5723 ,110.4423 ,117.8069 ,114.0247 ,304.9685 ,321.6601 ,109.0114 ,120.3600 ,195.9211 ,208.4348 ,214.5465 ,88.2353 ,7.3347 ,87.7533 ,26.0379 ,198.4337 ,25.5299 ,27.0467 ,228.7376 ,104.6958 ,285.1865 ,177.5740 ,310.5536 ,55.5047 ,180.5147 ,286.1941 ,27.7585 ,341.7221 ,62.3672 ,279.4352 ,354.5625 ,295.7581 ,115.1222 ,38.4760 ,185.1690 ,330.9685 ,105.6562 ,321.7532 ,51.0050 ,327.7734 ,11.4336 ,
  	   113.7847 ,325.1118 ,289.3883 ,326.5754 ,302.6587 ,268.6266 ,248.2543 ,64.1358 ,155.7497 ,56.8429 ,257.3368 ,240.4003 ,90.9311 ,23.1891 ,346.8189 ,290.9709 ,197.7372 ,194.8960 ,306.4654 ,163.1915 ,142.4558 ,121.9209 ,92.8689 ,8.7871 ,232.7180 ,150.0062 ,205.4173 ,22.4358 ,127.7796 ,49.7823 ,45.0464 ,93.2807 ,298.4164 ,143.2070 ,144.3896 ,220.4802 ,84.0707 ,2.6918 ,190.3326 ,180.3239 ,233.5823 ,157.7941 ,247.1447 ,263.3119 ,85.8149 ,178.2260 ,172.3777 ,81.0224 ,148.4086 ,201.7467 ,
  	   326.4982 ,330.3744 ,99.0811 ,232.7095 ,17.3510 ,25.7585 ,184.2090 ,315.8727 ,57.4084 ,275.7700 ,317.8834 ,112.2487 ,249.3205 ,305.6368 ,133.7812 ,252.4618 ,265.1105 ,214.0480 ,308.2598 ,322.7776 ,345.6284 ,205.6438 ,63.4593 ,90.2143 ,78.3427 ,205.0262 ,272.7900 ,18.7680 ,245.3891 ,258.1752 ,125.2733 ,185.4201 ,59.3273 ,262.7626 ,14.6551 ,353.2396 ,290.8597 ,226.2415 ,96.3094 ,328.6306 ,345.3980 ,50.0854 ,279.2726 ,303.0951 ,237.4982 ,252.1468 ,160.2211 ,332.7508 ,349.6347 ,137.6472 ,
  	   288.9762 ,155.8518 ,59.3115 ,117.1682 ,45.4788 ,327.1985 ,345.3927 ,42.9072 ,216.2445 ,146.9607 ,42.5124 ,106.3712 ,89.3579 ,269.8477 ,1.4432 ,68.3419 ,157.9583 ,7.5725 ,225.9096 ,218.0259 ,300.7196 ,74.3781 ,102.5214 ,195.2422 ,98.3613 ,210.8657 ,90.3176 ,246.0698 ,284.7927 ,291.1157 ,350.5018 ,196.3357 ,176.6913 ,308.0512 ,276.8643 ,205.3961 ,137.9723 ,102.2571 ,38.9301 ,290.7177 ,42.5058 ,269.0155 ,196.3034 ,347.3803 ,273.9836 ,350.4671 ,49.1738 ,180.1337 ,206.1282 ,112.0505 ,
  	   181.0917 ,128.4548 ,190.2218 ,0.3041 ,159.2332 ,161.8388 ,109.7277 ,143.7850 ,281.9114 ,246.0286 ,177.2277 ,233.1606 ,135.9210 ,73.4091 ,1.3952 ,99.9437 ,215.3391 ,317.3987 ,298.5916 ,183.9457 ,355.3265 ,166.1692 ,300.4537 ,147.2275 ,268.0670 ,355.5330 ,109.9212 ,61.3126 ,223.2121 ,191.1442 ,129.3919 ,1.2669 ,140.0986 ,153.3130 ,145.8907 ,310.0483 ,210.3941 ,264.1791 ,323.2473 ,269.5584 ,177.3727 ,268.4766 ,230.5279 ,233.5484 ,226.6831 ,146.5196 ,226.5343 ,228.1437 ,337.3625 ,281.6905 ,
  	   304.6565 ,276.2999 ,293.5173 ,217.9665 ,125.8020 ,95.2500 ,254.8872 ,314.6191 ,195.9288 ,54.7452 ,299.8711 ,174.4355 ,168.1569 ,16.3397 ,183.7011 ,268.1092 ,152.1352 ,127.8638 ,236.4637 ,7.1069 ,182.5789 ,340.6058 ,248.5611 ,144.6925 ,248.0070 ,217.7978 ,75.2002 ,74.7750 ,318.9691 ,96.8649 ,26.9585 ,299.0439 ,188.3512 ,132.5549 ,184.1468 ,265.2212 ,60.6793 ,235.1041 ,256.8373 ,293.4012 ,97.1138 ,219.4799 ,83.5610 ,201.9761 ,62.0507 ,284.3163 ,312.0184 ,118.6717 ,80.0347 ,346.9638 ,
  	   254.4085 ,303.7653 ,10.9924 ,323.7816 ,224.0827 ,113.9505 ,155.4356 ,274.1735 ,282.7483 ,68.3643 ,225.3191 ,59.6266 ,350.2979 ,159.6876 ,328.7322 ,262.1692 ,218.2536 ,94.3143 ,189.5732 ,49.9031 ,49.7153 ,257.6699 ,129.9923 ,270.4955 ,86.5777 ,258.5369 ,258.6517 ,109.9785 ,38.2988 ,142.9228 ,177.2501 ,35.9907 ,67.2341 ,19.9235 ,215.1049 ,319.9954 ,77.9608 ,12.4968 ,253.4125 ,293.3678 ,347.0838 ,220.7444 ,123.2795 ,301.6327 ,42.5042 ,249.3493 ,34.2831 ,143.8941 ,178.2082 ,136.0419 ,
  	   60.6951 ,83.4182 ,295.2540 ,166.5273 ,208.7758 ,76.2865 ,257.3766 ,118.8422 ,213.7027 ,327.4153 ,357.9816 ,16.6385 ,287.0794 ,308.7316 ,115.0468 ,137.9331 ,208.8914 ,330.7825 ,143.9743 ,316.8109 ,273.0818 ,54.8183 ,328.9248 ,5.4652 ,52.2642 ,239.3320 ,20.5631 ,136.6164 ,46.7924 ,166.6401 ,302.3929 ,326.1904 ,12.7691 ,21.9066 ,302.6247 ,15.4133 ,98.4925 ,42.2772 ,32.7736 ,9.9442 ,229.5047 ,268.0611 ,247.2377 ,304.4242 ,238.6858 ,140.2927 ,227.1827 ,349.0541 ,230.9772 ,87.5130 ,
  	   21.6663 ,336.6598 ,212.5784 ,125.8613 ,217.9270 ,201.6927 ,187.9818 ,21.8897 ,127.1619 ,148.5540 ,71.7726 ,316.8379 ,152.6831 ,238.4588 ,256.8767 ,267.5819 ,259.6015 ,270.7951 ,90.5690 ,351.5053 ,54.3635 ,330.7131 ,307.6448 ,306.7791 ,19.0121 ,32.8385 ,292.7001 ,168.9001 ,133.2911 ,354.4875 ,14.4425 ,191.3274 ,159.6059 ,46.1531 ,142.2678 ,254.7531 ,317.6336 ,8.8631 ,188.8234 ,32.5356 ,288.1416 ,30.8827 ,12.3096 ,138.3250 ,263.7382 ,112.7544 ,46.8018 ,286.0460 ,290.4910 ,308.1095 ,
  	   109.3480 ,152.9389 ,88.3404 ,200.5839 ,118.8386 ,121.9188 ,282.1037 ,344.2666 ,210.2905 ,37.6877 ,234.9270 ,161.5002 ,355.6910 ,258.9773 ,300.5230 ,252.4631 ,192.8228 ,322.8546 ,299.3821 ,104.8773 ,56.5315 ,133.3267 ,187.5880 ,35.0568 ,124.3365 ,206.9660 ,15.6869 ,293.3815 ,234.4021 ,112.9141 ,107.3956 ,126.9418 ,117.1039 ,269.4650 ,180.3805 ,189.4062 ,53.5523 ,329.1905 ,117.2063 ,117.9232 ,24.7846 ,352.5882 ,172.6912 ,328.6385 ,333.9422 ,349.1108 ,293.6265 ,333.1596 ,332.0242 ,288.4924 ,
  	   48.4492 ,188.5362 ,207.2174 ,357.2991 ,282.2215 ,253.0498 ,268.7937 ,130.1680 ,339.2329 ,231.6603 ,144.9269 ,167.2458 ,352.7118 ,191.5662 ,60.4071 ,53.4078 ,247.4072 ,202.5992 ,326.4503 ,66.4561 ,147.9992 ,262.0657 ,18.0378 ,35.7201 ,196.4548 ,95.6625 ,38.4975 ,94.2111 ,227.5708 ,189.4959 ,28.2588 ,26.2121 ,306.2257 ,231.5660 ,62.4122 ,310.2603 ,7.8658 ,132.5177 ,305.1467 ,255.7002 ,102.1509 ,320.8613 ,215.3081 ,311.5776 ,321.4056 ,153.1599 ,243.2161 ,196.0115 ,340.1047 ,287.3379 ,
  	   261.2947 ,293.0517 ,359.3376 ,92.3620 ,72.4909 ,268.8418 ,277.3197 ,185.1422 ,175.3473 ,145.3475 ,317.7709 ,286.6435 ,210.4551 ,14.4429 ,306.4110 ,165.0433 ,68.3138 ,107.7675 ,248.8804 ,1.9825 ,43.2161 ,108.9553 ,319.3889 ,268.8698 ,349.4850 ,195.4903 ,205.9086 ,198.4957 ,189.2258 ,195.1346 ,294.6843 ,343.2127 ,146.9883 ,226.7875 ,110.7934 ,108.6877 ,182.2742 ,211.0564 ,197.9980 ,351.5687 ,58.6696 ,229.1992 ,358.0312 ,265.0087 ,203.7271 ,132.6107 ,144.7700 ,337.1483 ,322.3190 ,241.0835 ,
  	   323.5492 ,333.0589 ,304.6837 ,138.0298 ,167.1713 ,286.5267 ,134.1479 ,269.7710 ,173.3113 ,121.1549 ,164.2134 ,41.9434 ,127.6188 ,149.4700 ,6.5389 ,61.9466 ,93.6839 ,308.8383 ,212.2478 ,103.3722 ,359.1816 ,92.8514 ,184.9638 ,266.2271 ,248.8754 ,156.0610 ,279.7192 ,174.8859 ,257.5674 ,176.8956 ,349.7381 ,257.8248 ,32.8958 ,46.6092 ,347.9453 ,82.5222 ,9.4090 ,91.1605 ,172.7233 ,342.7807 ,143.6868 ,260.4620 ,300.3705 ,32.0983 ,220.2811 ,358.4824 ,197.8545 ,192.4150 ,124.8129 ,340.5979 ,
  	   349.0557 ,37.1411 ,199.0202 ,151.0665 ,241.7926 ,42.7128 ,95.5203 ,100.3512 ,172.6967 ,285.5818 ,308.8251 ,283.1125 ,243.6505 ,31.3894 ,140.2981 ,240.7326 ,105.9292 ,182.8146 ,325.8282 ,41.8165 ,307.3956 ,38.0987 ,139.0912 ,325.9402 ,72.4320 ,187.4673 ,149.9775 ,319.6610 ,357.1433 ,103.8933 ,177.2916 ,322.2019 ,196.1264 ,77.2650 ,273.4784 ,121.3521 ,174.9508 ,3.0823 ,356.0281 ,236.6217 ,333.2926 ,348.7267 ,96.3121 ,194.5930 ,158.4904 ,273.5479 ,303.2588 ,82.2817 ,98.8433 ,254.2542 ,
  	   148.1915 ,46.8726 ,70.3118 ,201.9058 ,215.4580 ,345.6258 ,191.8008 ,219.2331 ,53.5877 ,148.9687 ,100.7249 ,250.3522 ,96.1406 ,77.1841 ,132.3664 ,169.3977 ,121.8222 ,218.0636 ,65.2333 ,316.7677 ,249.9017 ,192.5148 ,20.9384 ,117.3624 ,248.4387 ,232.2231 ,292.3035 ,320.9431 ,113.5319 ,177.7430 ,118.8150 ,46.0520 ,50.4422 ,92.3290 ,31.6904 ,193.9772 ,253.0521 ,202.7061 ,246.5160 ,81.4493 ,71.7856 ,204.3269 ,318.3428 ,152.0152 ,1.5252 ,7.2186 ,109.9097 ,221.5347 ,30.4436 ,80.8237 ,
  	   245.0486 ,354.5971 ,122.7862 ,216.4100 ,186.6347 ,8.3249 ,118.7404 ,50.1988 ,90.2958 ,277.1932 ,245.2329 ,14.7683 ,27.8550 ,260.9745 ,37.1555 ,114.1272 ,96.9615 ,17.9159 ,11.2212 ,50.0525 ,143.7578 ,336.1341 ,229.8161 ,87.1420 ,244.6719 ,98.5079 ,185.4857 ,115.8580 ,341.5215 ,126.8505 ,289.2826 ,230.8295 ,303.5972 ,218.2177 ,313.3386 ,145.8587 ,244.4410 ,223.4294 ,189.9841 ,203.1984 ,192.8743 ,141.7575 ,323.3950 ,227.7826 ,197.6843 ,19.4181 ,183.0701 ,63.0528 ,77.4084 ,156.4604 ,
  	   196.5445 ,90.1484 ,97.5364 ,190.8527 ,170.3643 ,145.1835 ,37.3513 ,134.4520 ,235.5917 ,195.9116 ,196.1110 ,303.7745 ,260.3387 ,246.4521 ,10.9489 ,110.9261 ,245.6684 ,56.0782 ,328.8503 ,51.0936 ,316.4837 ,77.8566 ,302.9723 ,305.3627 ,120.7673 ,319.8933 ,57.5164 ,305.6794 ,137.4244 ,158.2983 ,42.4295 ,216.3619 ,97.1121 ,240.0765 ,287.7797 ,217.3262 ,2.9465 ,342.8407 ,331.0852 ,231.4567 ,136.6223 ,202.2890 ,317.8123 ,165.4304 ,280.5186 ,215.4812 ,152.0205 ,336.0696 ,147.0351 ,218.0805 ,
  	   19.1787 ,169.4750 ,13.4691 ,253.4878 ,0.2125 ,15.1436 ,40.0052 ,50.2470 ,182.9082 ,128.2638 ,97.5252 ,354.1045 ,327.2400 ,235.7504 ,288.7513 ,295.0950 ,88.2624 ,290.9830 ,86.3322 ,202.4484 ,128.7781 ,57.1173 ,279.6676 ,329.8830 ,112.9315 ,316.7145 ,124.6522 ,236.7199 ,358.4843 ,277.9455 ,20.0402 ,156.5542 ,135.4692 ,105.8154 ,293.8088 ,158.7673 ,251.7265 ,228.5752 ,186.8385 ,20.1712 ,242.2927 ,320.8979 ,61.9918 ,231.3880 ,175.4782 ,122.7544 ,255.7536 ,351.0716 ,7.7993 ,323.0301 ,
  	   137.9659 ,300.1854 ,62.8961 ,257.9730 ,35.8907 ,120.8197 ,349.1671 ,236.3816 ,282.4286 ,166.0700 ,169.6201 ,177.3451 ,278.3359 ,260.3699 ,69.7565 ,158.6176 ,195.1286 ,205.7143 ,333.6375 ,302.3090 ,53.9572 ,135.4035 ,39.2301 ,9.4406 ,26.8509 ,65.8676 ,275.7878 ,240.1997 ,287.2336 ,103.8612 ,55.9840 ,349.9561 ,297.3690 ,340.8415 ,6.7633 ,142.7571 ,228.1674 ,264.9868 ,328.5542 ,193.5834 ,140.6853 ,1.9166 ,289.3908 ,353.5769 ,326.6087 ,238.4167 ,123.2912 ,86.0941 ,279.0071 ,336.7546 ,
  	   345.7174 ,63.2187 ,210.7270 ,184.7226 ,153.8731 ,285.9842 ,336.8817 ,260.8649 ,252.1101 ,248.6212 ,235.2804 ,193.2314 ,89.2497 ,280.6117 ,42.8736 ,231.7997 ,139.3154 ,201.5865 ,230.9171 ,172.4125 ,352.1139 ,86.1095 ,4.3806 ,343.8929 ,112.3228 ,100.1061 ,149.6013 ,214.1880 ,355.0012 ,254.7089 ,114.5953 ,192.4878 ,161.5268 ,180.5714 ,150.3390 ,60.3424 ,142.3743 ,140.0721 ,72.2590 ,294.0907 ,129.5967 ,54.5351 ,204.0748 ,304.1436 ,281.0020 ,223.9345 ,263.1737 ,121.0012 ,51.3761 ,91.8035 ,
  	   125.7673 ,100.4882 ,168.3941 ,53.6516 ,46.8942 ,90.9806 ,70.7413 ,288.6122 ,193.5205 ,71.4280 ,154.5182 ,313.8896 ,207.9404 ,199.4091 ,140.8745 ,70.5015 ,225.1458 ,27.7738 ,283.0284 ,20.7089 ,268.6850 ,137.7465 ,245.6681 ,212.7619 ,46.5032 ,193.8608 ,26.7003 ,86.8386 ,137.4008 ,102.8416 ,238.2334 ,355.2605 ,128.4701 ,301.8950 ,81.0358 ,255.3591 ,125.1793 ,192.7308 ,31.8900 ,297.8472 ,75.1806 ,166.8430 ,104.5065 ,291.6731 ,213.3341 ,221.4666 ,271.7095 ,91.7628 ,20.9693 ,298.2799 ,
  	   113.6179 ,292.4176 ,344.3902 ,226.5088 ,37.1851 ,307.4354 ,228.0341 ,88.5237 ,74.8339 ,182.7797 ,43.7637 ,326.1672 ,254.8304 ,294.9416 ,138.1754 ,332.3489 ,48.2237 ,257.8500 ,91.6574 ,1.3074 ,43.5209 ,72.5559 ,274.8043 ,136.0980 ,173.5310 ,220.8895 ,96.3577 ,229.8361 ,241.7659 ,331.6929 ,181.0321 ,307.9030 ,348.3906 ,276.8023 ,151.6291 ,97.9127 ,35.1835 ,299.1697 ,46.6560 ,201.4246 ,163.4151 ,16.1447 ,77.1616 ,296.2428 ,193.9175 ,332.7821 ,326.8706 ,33.8499 ,244.1221 ,15.3569 ,
  	   152.1600 ,159.0390 ,344.4742 ,214.3143 ,68.4002 ,183.5090 ,187.8584 ,70.9469 ,129.5033 ,315.8981 ,353.3295 ,279.6719 ,23.2205 ,326.1156 ,165.0454 ,300.2602 ,63.6408 ,53.1665 ,326.3984 ,102.7884 ,15.5000 ,180.3774 ,356.6046 ,300.7793 ,142.6679 ,357.5064 ,286.8013 ,303.1437 ,232.5985 ,141.9773 ,326.0555 ,169.4265 ,336.4712 ,198.7888 ,327.5487 ,171.7763 ,153.6555 ,211.9256 ,114.2318 ,53.7831 ,212.1597 ,306.3467 ,99.9994 ,311.4077 ,283.3664 ,279.2433 ,149.4469 ,359.5523 ,284.7162 ,207.2336 ,
  	   40.8636 ,206.5736 ,5.1772 ,324.7951 ,121.2110 ,132.6042 ,198.3179 ,229.4870 ,209.7817 ,174.5731 ,228.3679 ,304.9712 ,160.6354 ,180.0286 ,291.7249 ,1.2262 ,57.8558 ,117.0108 ,77.0175 ,322.5636 ,53.3578 ,38.8392 ,114.1923 ,183.1107 ,295.7331 ,358.4344 ,306.6731 ,219.1815 ,13.5367 ,22.8472 ,227.0650 ,295.1576 ,95.5845 ,348.9188 ,198.1394 ,206.5576 ,222.7039 ,26.9691 ,61.3397 ,337.0292 ,96.2263 ,29.9855 ,101.6744 ,261.4126 ,94.6111 ,75.8094 ,99.7666 ,172.9518 ,265.5177 ,108.4763 ,
  	   314.4635 ,351.3177 ,295.9259 ,27.0452 ,113.5651 ,333.2829 ,309.3784 ,47.9712 ,159.2008 ,131.0193 ,269.0891 ,10.3355 ,113.5717 ,269.9207 ,319.2733 ,14.6255 ,211.8072 ,238.8991 ,314.2501 ,152.8486 ,350.2979 ,71.0733 ,41.3145 ,46.8164 ,211.2206 ,44.0786 ,95.9749 ,70.6686 ,19.9057 ,346.4580 ,120.5731 ,347.0457 ,260.3642 ,79.1169 ,335.7168 ,3.3667 ,353.3957 ,11.6152 ,91.1928 ,198.7046 ,3.3040 ,275.2963 ,30.4755 ,294.1511 ,12.6376 ,190.1368 ,75.3973 ,103.9551 ,176.5744 ,133.6961 ,
  	   141.1128 ,235.2350 ,70.2869 ,65.3404 ,246.3818 ,106.9066 ,335.8639 ,153.4464 ,170.6476 ,8.3413 ,7.4360 ,37.7164 ,225.2261 ,239.2356 ,342.7911 ,155.6890 ,254.7614 ,123.6968 ,26.6623 ,151.2668 ,252.5848 ,289.5206 ,342.7141 ,299.5823 ,202.9012 ,198.1318 ,180.3943 ,171.9383 ,244.9770 ,207.2543 ,308.5783 ,162.0267 ,169.6230 ,299.5485 ,243.2291 ,188.8024 ,202.8407 ,290.0535 ,218.6575 ,93.2941 ,111.6876 ,217.6578 ,16.5053 ,164.7275 ,321.0865 ,83.5718 ,159.8962 ,251.8217 ,333.1814 ,250.6584 ,
  	   225.2989 ,138.2022 ,157.4493 ,231.1009 ,128.2752 ,282.5537 ,2.9486 ,270.5103 ,267.1368 ,110.3184 ,5.3859 ,121.7372 ,212.1069 ,283.3009 ,313.3318 ,75.0827 ,29.4253 ,43.1590 ,356.0574 ,232.3572 ,46.2113 ,248.6755 ,345.4120 ,218.6773 ,83.7260 ,346.4602 ,252.1992 ,65.8743 ,275.8385 ,181.5029 ,206.6555 ,131.6834 ,105.7505 ,151.3572 ,189.5048 ,166.1195 ,311.8556 ,26.7140 ,71.6362 ,337.5019 ,218.8289 ,222.3107 ,226.7100 ,87.6582 ,142.0845 ,75.6534 ,54.7140 ,356.2244 ,267.7731 ,316.4894 ,
  	   0.5268 ,253.6096 ,110.6143 ,179.2479 ,243.0905 ,11.2273 ,133.4734 ,199.4024 ,314.7762 ,184.7545 ,114.3300 ,217.3539 ,210.1003 ,105.2240 ,197.2986 ,99.4042 ,4.0655 ,111.8612 ,31.1151 ,177.0809 ,180.4136 ,313.2799 ,269.2464 ,269.7761 ,356.2720 ,95.2841 ,134.1848 ,83.0006 ,36.8953 ,185.4825 ,184.0782 ,46.7010 ,332.1148 ,352.2612 ,24.5901 ,1.1416 ,22.2470 ,263.4230 ,306.9077 ,23.8200 ,3.2264 ,193.6608 ,119.7761 ,6.7456 ,3.1677 ,76.0894 ,72.0395 ,106.3307 ,198.2397 ,90.4967 ,
  	   84.0660 ,75.8696 ,319.3204 ,85.8929 ,199.9189 ,162.9480 ,119.3058 ,146.4337 ,5.7568 ,66.6172 ,230.4501 ,274.1354 ,78.6131 ,63.5507 ,326.0493 ,35.2009 ,286.1498 ,316.0987 ,52.6676 ,299.8708 ,54.0204 ,15.5185 ,103.0440 ,123.9564 ,212.2345 ,159.3078 ,285.6445 ,239.3161 ,42.9098 ,72.8524 ,268.6187 ,41.7367 ,342.9487 ,292.1616 ,79.1412 ,103.0001 ,90.7650 ,152.2239 ,89.5103 ,11.6147 ,90.6362 ,70.1275 ,125.9727 ,163.5353 ,314.7524 ,237.4401 ,221.5736 ,311.2304 ,139.1520 ,153.3938 ,
  	   88.0182 ,298.8727 ,315.8499 ,327.8984 ,217.7735 ,40.9818 ,26.0167 ,287.1124 ,318.7678 ,191.6168 ,331.4763 ,335.0782 ,271.7104 ,133.3960 ,164.2831 ,126.6783 ,142.5779 ,169.6735 ,6.1597 ,45.8441 ,60.4856 ,204.0535 ,313.7794 ,256.1025 ,53.8183 ,164.7662 ,225.8295 ,48.6688 ,28.6880 ,220.3338 ,84.7542 ,232.2207 ,61.7555 ,308.1259 ,111.5065 ,154.2092 ,197.9879 ,319.0853 ,329.8959 ,304.1253 ,246.4257 ,24.9076 ,67.2442 ,192.4583 ,354.6459 ,261.4127 ,68.9989 ,128.1590 ,346.4873 ,182.7886 ,
  	   313.3146 ,308.8782 ,281.4358 ,225.7350 ,239.7036 ,123.1478 ,43.3495 ,341.4819 ,11.7469 ,97.5186 ,221.0025 ,347.3754 ,75.6604 ,88.9090 ,305.2469 ,117.7438 ,145.0639 ,129.5065 ,17.8032 ,339.0559 ,251.1829 ,2.4573 ,34.9720 ,48.7635 ,132.7992 ,320.5159 ,50.7095 ,82.1075 ,112.1197 ,183.8500 ,324.3923 ,194.2046 ,325.2796 ,195.0937 ,155.5647 ,313.7269 ,209.1007 ,170.9917 ,184.4824 ,128.0268 ,155.9165 ,26.6971 ,73.8779 ,274.6787 ,48.0904 ,74.9695 ,58.8937 ,130.6374 ,17.7437 ,129.7186 ,
  	   219.4900 ,244.0708 ,312.2449 ,31.3480 ,231.7762 ,70.6731 ,123.2730 ,207.0466 ,301.6632 ,241.4191 ,354.7076 ,6.4612 ,113.7925 ,172.9306 ,13.0340 ,18.8541 ,132.0380 ,201.2970 ,48.7854 ,24.5901 ,114.7811 ,266.9480 ,204.1823 ,358.8496 ,217.8375 ,320.5425 ,206.2401 ,173.1312 ,149.5963 ,25.7367 ,22.6552 ,237.0265 ,309.3022 ,6.8574 ,64.8816 ,117.8882 ,112.7046 ,300.3107 ,90.8638 ,110.2369 ,175.5303 ,342.2906 ,106.0254 ,228.1336 ,17.4958 ,155.3184 ,333.7967 ,78.2658 ,128.3262 ,235.4921 ,
  	   203.5949 ,207.3714 ,219.0790 ,243.1392 ,116.1590 ,126.6178 ,142.9222 ,188.0413 ,204.1206 ,314.6275 ,142.5010 ,161.7292 ,299.7556 ,349.5870 ,87.4424 ,262.9549 ,89.1403 ,266.8033 ,13.8698 ,182.5662 ,205.1923 ,251.8529 ,330.1310 ,286.2343 ,202.7090 ,178.9829 ,4.7615 ,198.9596 ,202.4008 ,267.1567 ,59.5433 ,211.9181 ,18.5697 ,261.3239 ,295.7790 ,157.5994 ,247.5670 ,238.4318 ,109.2955 ,31.7682 ,272.8792 ,128.5476 ,58.0955 ,159.1944 ,299.8588 ,343.5071 ,204.2419 ,349.1483 ,62.4329 ,176.5503 ,
  	   3.0158 ,84.2279 ,315.5617 ,21.3817 ,235.5949 ,183.4349 ,355.5277 ,357.6947 ,44.4028 ,94.3465 ,356.9107 ,118.7798 ,64.9723 ,328.2382 ,222.1999 ,110.9368 ,199.5792 ,153.8665 ,164.8746 ,198.7647 ,61.1201 ,221.6173 ,343.8607 ,213.1343 ,283.4999 ,101.7129 ,55.6545 ,2.3179 ,353.2748 ,42.8624 ,136.8053 ,235.7004 ,264.4558 ,222.5277 ,158.2426 ,293.3762 ,159.2495 ,300.7093 ,19.4489 ,259.9238 ,35.0273 ,139.5218 ,159.6195 ,65.5154 ,161.6214 ,307.0420 ,13.1068 ,69.8105 ,351.2216 ,161.9879};
#endif

#ifdef INPUT_DATA_IN_CCM
   __attribute__((section(".ccmramdata")))
#endif
    int array_len = sizeof(arr_keys)/sizeof(arr_keys[0]);

#ifdef INPUT_DATA_IN_CCM
   __attribute__((section(".ccmramdata")))
#endif
    int input_len = sizeof(arr_input)/sizeof(arr_input[0]);

/* USER CODE END PV */

void SystemClock_Config(void);
static void MX_GPIO_Init(void);
static void MX_TIM2_Init(void);
static void MX_USART1_UART_Init(void);

int main(void)
{
  /* USER CODE BEGIN 1 */
  int time1 __attribute__((aligned (4))) = 0;
  int time2 __attribute__((aligned (4))) = 0;

  /* USER CODE END 1 */

  /* MCU Configuration--------------------------------------------------------*/

  /* Reset of all peripherals, Initializes the Flash interface and the Systick. */
  HAL_Init();

  /* Configure the system clock */
  SystemClock_Config();

  /* Initialize all configured peripherals */
  MX_GPIO_Init();
  MX_TIM2_Init();
  MX_USART1_UART_Init();
  /* USER CODE BEGIN 2 */
//  TIM2->CR1&=~TIM_CR1_DIR;

  HAL_TIM_Base_Start(&htim2);
  // enable update interrupts
  TIM2->DIER|=TIM_DIER_UIE;

////////////////////////////////////////////////////////////////////start counting time

  overflow_cnt = 0;
  time1 = TIM2->CNT;

  computeArraySin(&arr_input[0], &arr_keys[0], &arr_values[0], array_len, input_len);

  time2 = TIM2->CNT;
  ////////////////////////////////////////////////////////////////////end counting time
  tim_cnt = time2 -time1;
  execution_time = overflow_cnt*1000 + (double)tim_cnt/(1000);

  uint8_t msg[40] = {'\0'};

  sprintf(msg,"\n\rLookUpTable:\n\r%d", (int)(execution_time*1000));
  HAL_UART_Transmit(&huart1, msg, sizeof(msg), 0xffff);

  //execution time is in ms

  /* USER CODE END 2 */

  /* Infinite loop */
  /* USER CODE BEGIN WHILE */
  int  i = 0;
  while (i<10)
  {
	  MX_TIM2_Init();
	  HAL_TIM_Base_Start(&htim2);
	  overflow_cnt = 0;
	  time1 = TIM2->CNT;

	  computeArraySin(&arr_input[0], &arr_keys[0], &arr_values[0], array_len, input_len);

	  time2 = TIM2->CNT;
	  ////////////////////////////////////////////////////////////////////end counting time
	  tim_cnt = time2 -time1;
	  execution_time = overflow_cnt*1000 + (double)tim_cnt/(1000);

	  uint8_t msg[40] = {'\0'};

	  sprintf(msg,"\n\r%dth: rLookUpTable:\n\r%d", i,(int)(execution_time*1000));
	  HAL_UART_Transmit(&huart1, msg, sizeof(msg), 0xffff);
	  i++;
    /* USER CODE END WHILE */

    /* USER CODE BEGIN 3 */
  }
  return 0;
  /* USER CODE END 3 */
}

void SystemClock_Config(void)
{
  RCC_OscInitTypeDef RCC_OscInitStruct = {0};
  RCC_ClkInitTypeDef RCC_ClkInitStruct = {0};
  RCC_PeriphCLKInitTypeDef PeriphClkInit = {0};

  /** Initializes the RCC Oscillators according to the specified parameters
  * in the RCC_OscInitTypeDef structure.
  */
  RCC_OscInitStruct.OscillatorType = RCC_OSCILLATORTYPE_HSE;
  RCC_OscInitStruct.HSEState = RCC_HSE_ON;
  RCC_OscInitStruct.HSEPredivValue = RCC_HSE_PREDIV_DIV1;
  RCC_OscInitStruct.HSIState = RCC_HSI_ON;
  RCC_OscInitStruct.PLL.PLLState = RCC_PLL_ON;
  RCC_OscInitStruct.PLL.PLLSource = RCC_PLLSOURCE_HSE;
  RCC_OscInitStruct.PLL.PLLMUL = RCC_PLL_MUL3;
  if (HAL_RCC_OscConfig(&RCC_OscInitStruct) != HAL_OK)
  {
    Error_Handler();
  }
  /** Initializes the CPU, AHB and APB buses clocks
  */
  RCC_ClkInitStruct.ClockType = RCC_CLOCKTYPE_HCLK|RCC_CLOCKTYPE_SYSCLK
                              |RCC_CLOCKTYPE_PCLK1|RCC_CLOCKTYPE_PCLK2;
  RCC_ClkInitStruct.SYSCLKSource = RCC_SYSCLKSOURCE_PLLCLK;
  RCC_ClkInitStruct.AHBCLKDivider = RCC_SYSCLK_DIV1;
  RCC_ClkInitStruct.APB1CLKDivider = RCC_HCLK_DIV2;
  RCC_ClkInitStruct.APB2CLKDivider = RCC_HCLK_DIV1;

  if (HAL_RCC_ClockConfig(&RCC_ClkInitStruct, FLASH_LATENCY_0) != HAL_OK)
  {
    Error_Handler();
  }
  PeriphClkInit.PeriphClockSelection = RCC_PERIPHCLK_USART1;
  PeriphClkInit.Usart1ClockSelection = RCC_USART1CLKSOURCE_PCLK2;
  if (HAL_RCCEx_PeriphCLKConfig(&PeriphClkInit) != HAL_OK)
  {
    Error_Handler();
  }
}

static void MX_TIM2_Init(void)
{

  TIM_ClockConfigTypeDef sClockSourceConfig = {0};
  TIM_MasterConfigTypeDef sMasterConfig = {0};

  htim2.Instance = TIM2;
  htim2.Init.Prescaler = (24-1);
  htim2.Init.CounterMode = TIM_COUNTERMODE_UP;
  htim2.Init.Period = (1000000-1);
  htim2.Init.ClockDivision = TIM_CLOCKDIVISION_DIV1;
  htim2.Init.AutoReloadPreload = TIM_AUTORELOAD_PRELOAD_DISABLE;
  if (HAL_TIM_Base_Init(&htim2) != HAL_OK)
  {
    Error_Handler();
  }
  sClockSourceConfig.ClockSource = TIM_CLOCKSOURCE_INTERNAL;
  if (HAL_TIM_ConfigClockSource(&htim2, &sClockSourceConfig) != HAL_OK)
  {
    Error_Handler();
  }
  sMasterConfig.MasterOutputTrigger = TIM_TRGO_RESET;
  sMasterConfig.MasterSlaveMode = TIM_MASTERSLAVEMODE_DISABLE;
  if (HAL_TIMEx_MasterConfigSynchronization(&htim2, &sMasterConfig) != HAL_OK)
  {
    Error_Handler();
  }

}

static void MX_USART1_UART_Init(void)
{

  huart1.Instance = USART1;
  huart1.Init.BaudRate = 38400;
  huart1.Init.WordLength = UART_WORDLENGTH_8B;
  huart1.Init.StopBits = UART_STOPBITS_1;
  huart1.Init.Parity = UART_PARITY_NONE;
  huart1.Init.Mode = UART_MODE_TX_RX;
  huart1.Init.HwFlowCtl = UART_HWCONTROL_NONE;
  huart1.Init.OverSampling = UART_OVERSAMPLING_16;
  huart1.Init.OneBitSampling = UART_ONE_BIT_SAMPLE_DISABLE;
  huart1.AdvancedInit.AdvFeatureInit = UART_ADVFEATURE_NO_INIT;
  if (HAL_UART_Init(&huart1) != HAL_OK)
  {
    Error_Handler();
  }

}

static void MX_GPIO_Init(void)
{

  /* GPIO Ports Clock Enable */
  __HAL_RCC_GPIOF_CLK_ENABLE();
  __HAL_RCC_GPIOC_CLK_ENABLE();

}

/* USER CODE BEGIN 4 */
void HAL_TIM_PeriodElapsedCallback(TIM_HandleTypeDef* htim)
{
	overflow_cnt++;

}

/* USER CODE END 4 */

void Error_Handler(void)
{
  __disable_irq();
  while (1)
  {
  }
}

/************************ (C) COPYRIGHT STMicroelectronics *****END OF FILE****/
